[part 1 of 2: package /RootP_ASWC_A28]
AUTOSAR XML (schema 4-2-1)
package /RootP_ASWC_A28
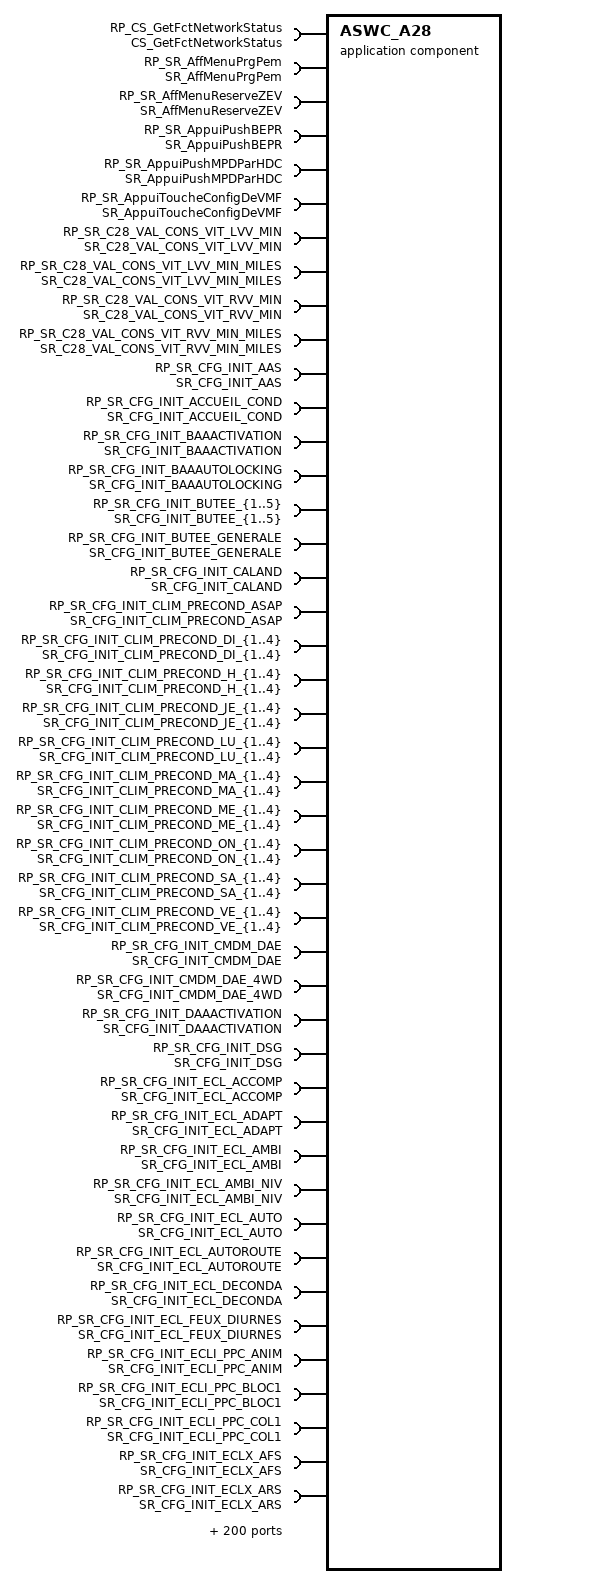
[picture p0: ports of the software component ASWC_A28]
  application sw component type ASWC_A28
    277 x provide/require port:
      PRP_SR_ButeeXvv{1..5}DeMenuPerso: nonqueued-receiver-com-spec{data-element=ButeeXvv{1..5}DeMenuPerso, enable-update=0, handle-data-status=1, handle-never-received=0, init-value=CONST_tBYTE_0:0}, provided-required-interface=SR_ButeeXvv{1..5}DeMenuPerso
      PRP_SR_DdeAccesJDADeVMF: nonqueued-receiver-com-spec{data-element=DdeAccesJDADeVMF, enable-update=0, handle-data-status=1, handle-never-received=0, init-value=CONST_tLOG_0:0}, provided-required-interface=SR_DdeAccesJDADeVMF
      PRP_SR_DdeAllumPlafDeVMF: nonqueued-receiver-com-spec{data-element=DdeAllumPlafDeVMF, enable-update=0, handle-data-status=1, handle-never-received=0, init-value=CONST_tLOG_0:0}, provided-required-interface=SR_DdeAllumPlafDeVMF
      PRP_SR_DdeBlackPanelDeVMF: nonqueued-receiver-com-spec{data-element=DdeBlackPanelDeVMF, enable-update=0, handle-data-status=1, handle-never-received=0, init-value=CONST_tLOG_0:0}, provided-required-interface=SR_DdeBlackPanelDeVMF
      PRP_SR_DdeCheckTcfg: nonqueued-receiver-com-spec{data-element=DdeCheckTcfg, enable-update=0, handle-data-status=1, handle-never-received=0, init-value=CONST_tLOG_0:0}, provided-required-interface=SR_DdeCheckTcfg
      PRP_SR_DdeColorisationCMBDeVMF: nonqueued-receiver-com-spec{data-element=DdeColorisationCMBDeVMF, enable-update=0, handle-data-status=1, handle-never-received=0, init-value=CONST_tLOG_0:0}, provided-required-interface=SR_DdeColorisationCMBDeVMF
      PRP_SR_DdeConfigToucheDeVMF: nonqueued-receiver-com-spec{data-element=DdeConfigToucheDeVMF, enable-update=0, handle-data-status=1, handle-never-received=0, init-value=CONST_tLOG_0:0}, provided-required-interface=SR_DdeConfigToucheDeVMF
      PRP_SR_DdePersoCMBDeVMF: nonqueued-receiver-com-spec{data-element=DdePersoCMBDeVMF, enable-update=0, handle-data-status=1, handle-never-received=0, init-value=CONST_tLOG_0:0}, provided-required-interface=SR_DdePersoCMBDeVMF
      PRP_SR_DispoDmdMenuPrecond: nonqueued-receiver-com-spec{data-element=DispoDmdMenuPrecond, enable-update=0, handle-data-status=1, handle-never-received=0, init-value=CONST_tLOG_0:0}, provided-required-interface=SR_DispoDmdMenuPrecond
      PRP_SR_DispoDmdMenuRecharge: nonqueued-receiver-com-spec{data-element=DispoDmdMenuRecharge, enable-update=0, handle-data-status=1, handle-never-received=0, init-value=CONST_tBYTE_0b01:0b01}, provided-required-interface=SR_DispoDmdMenuRecharge
      PRP_SR_DispoEtatMenuPrgPem: nonqueued-receiver-com-spec{data-element=DispoEtatMenuPrgPem, enable-update=0, handle-data-status=1, handle-never-received=0, init-value=CONST_tLOG_0:0}, provided-required-interface=SR_DispoEtatMenuPrgPem
      PRP_SR_DispoEtatMenuReserveZEV: nonqueued-receiver-com-spec{data-element=DispoEtatMenuReserveZEV, enable-update=0, handle-data-status=1, handle-never-received=0, init-value=CONST_tLOG_0:0}, provided-required-interface=SR_DispoEtatMenuReserveZEV
      PRP_SR_DmdmCGEPVReserveZEV: nonqueued-receiver-com-spec{data-element=DmdmCGEPVReserveZEV, enable-update=0, handle-data-status=1, handle-never-received=0, init-value=CONST_tLOG_0:0}, provided-required-interface=SR_DmdmCGEPVReserveZEV
      PRP_SR_DmdMenuSelPrgDi: nonqueued-receiver-com-spec{data-element=DmdMenuSelPrgDi, enable-update=0, handle-data-status=1, handle-never-received=0, init-value=CONST_tLOG_0:0}, provided-required-interface=SR_DmdMenuSelPrgDi
      PRP_SR_DmdMenuSelPrgJe: nonqueued-receiver-com-spec{data-element=DmdMenuSelPrgJe, enable-update=0, handle-data-status=1, handle-never-received=0, init-value=CONST_tLOG_0:0}, provided-required-interface=SR_DmdMenuSelPrgJe
      PRP_SR_DmdMenuSelPrgLu: nonqueued-receiver-com-spec{data-element=DmdMenuSelPrgLu, enable-update=0, handle-data-status=1, handle-never-received=0, init-value=CONST_tLOG_0:0}, provided-required-interface=SR_DmdMenuSelPrgLu
      PRP_SR_DmdMenuSelPrgMa: nonqueued-receiver-com-spec{data-element=DmdMenuSelPrgMa, enable-update=0, handle-data-status=1, handle-never-received=0, init-value=CONST_tLOG_0:0}, provided-required-interface=SR_DmdMenuSelPrgMa
      PRP_SR_DmdMenuSelPrgMe: nonqueued-receiver-com-spec{data-element=DmdMenuSelPrgMe, enable-update=0, handle-data-status=1, handle-never-received=0, init-value=CONST_tLOG_0:0}, provided-required-interface=SR_DmdMenuSelPrgMe
      PRP_SR_DmdMenuSelPrgSa: nonqueued-receiver-com-spec{data-element=DmdMenuSelPrgSa, enable-update=0, handle-data-status=1, handle-never-received=0, init-value=CONST_tLOG_0:0}, provided-required-interface=SR_DmdMenuSelPrgSa
      PRP_SR_DmdMenuSelPrgVe: nonqueued-receiver-com-spec{data-element=DmdMenuSelPrgVe, enable-update=0, handle-data-status=1, handle-never-received=0, init-value=CONST_tLOG_0:0}, provided-required-interface=SR_DmdMenuSelPrgVe
      PRP_SR_DmdmPrgHcEnd: nonqueued-receiver-com-spec{data-element=DmdmPrgHcEnd, enable-update=0, handle-data-status=1, handle-never-received=0, init-value=CONST_tDWORD_0:0}, provided-required-interface=SR_DmdmPrgHcEnd
      PRP_SR_DmdmPrgHcStart: nonqueued-receiver-com-spec{data-element=DmdmPrgHcStart, enable-update=0, handle-data-status=1, handle-never-received=0, init-value=CONST_tDWORD_0:0}, provided-required-interface=SR_DmdmPrgHcStart
      PRP_SR_DmdmPrgPemDi: nonqueued-receiver-com-spec{data-element=DmdmPrgPemDi, enable-update=0, handle-data-status=1, handle-never-received=0, init-value=CONST_tDWORD_0:0}, provided-required-interface=SR_DmdmPrgPemDi
      PRP_SR_DmdmPrgPemJe: nonqueued-receiver-com-spec{data-element=DmdmPrgPemJe, enable-update=0, handle-data-status=1, handle-never-received=0, init-value=CONST_tDWORD_0:0}, provided-required-interface=SR_DmdmPrgPemJe
      PRP_SR_DmdmPrgPemLu: nonqueued-receiver-com-spec{data-element=DmdmPrgPemLu, enable-update=0, handle-data-status=1, handle-never-received=0, init-value=CONST_tDWORD_0:0}, provided-required-interface=SR_DmdmPrgPemLu
      PRP_SR_DmdmPrgPemMa: nonqueued-receiver-com-spec{data-element=DmdmPrgPemMa, enable-update=0, handle-data-status=1, handle-never-received=0, init-value=CONST_tDWORD_0:0}, provided-required-interface=SR_DmdmPrgPemMa
      PRP_SR_DmdmPrgPemMe: nonqueued-receiver-com-spec{data-element=DmdmPrgPemMe, enable-update=0, handle-data-status=1, handle-never-received=0, init-value=CONST_tDWORD_0:0}, provided-required-interface=SR_DmdmPrgPemMe
      PRP_SR_DmdmPrgPemSa: nonqueued-receiver-com-spec{data-element=DmdmPrgPemSa, enable-update=0, handle-data-status=1, handle-never-received=0, init-value=CONST_tDWORD_0:0}, provided-required-interface=SR_DmdmPrgPemSa
      PRP_SR_DmdmPrgPemVe: nonqueued-receiver-com-spec{data-element=DmdmPrgPemVe, enable-update=0, handle-data-status=1, handle-never-received=0, init-value=CONST_tDWORD_0:0}, provided-required-interface=SR_DmdmPrgPemVe
      PRP_SR_EclAccompDeMenuPerso: nonqueued-receiver-com-spec{data-element=EclAccompDeMenuPerso, enable-update=0, handle-data-status=1, handle-never-received=0, init-value=CONST_t_cAccomp_0:0}, provided-required-interface=SR_EclAccompDeMenuPerso
      PRP_SR_EclDecondaDeMenuPerso: nonqueued-receiver-com-spec{data-element=EclDecondaDeMenuPerso, enable-update=0, handle-data-status=1, handle-never-received=0, init-value=CONST_t_cDeconda_0:0}, provided-required-interface=SR_EclDecondaDeMenuPerso
      PRP_SR_EtatMenuAccueilCond: nonqueued-receiver-com-spec{data-element=EtatMenuAccueilCond, enable-update=0, handle-data-status=1, handle-never-received=0, init-value=CONST_tLOG_0:0}, provided-required-interface=SR_EtatMenuAccueilCond
      PRP_SR_EtatMenuActButee{1..5}XVV: nonqueued-receiver-com-spec{data-element=EtatMenuActButee{1..5}XVV, enable-update=0, handle-data-status=1, handle-never-received=0, init-value=CONST_tLOG_0:0}, provided-required-interface=SR_EtatMenuActButee{1..5}XVV
      PRP_SR_EtatMenuActButeeGenXVV: nonqueued-receiver-com-spec{data-element=EtatMenuActButeeGenXVV, enable-update=0, handle-data-status=1, handle-never-received=0, init-value=CONST_tLOG_0:0}, provided-required-interface=SR_EtatMenuActButeeGenXVV
      PRP_SR_EtatMenuARCSensNiv: nonqueued-receiver-com-spec{data-element=EtatMenuARCSensNiv, enable-update=0, handle-data-status=1, handle-never-received=0, init-value=CONST_tBILOG_2:2}, provided-required-interface=SR_EtatMenuARCSensNiv
      PRP_SR_EtatMenuBAAActivation: nonqueued-receiver-com-spec{data-element=EtatMenuBAAActivation, enable-update=0, handle-data-status=1, handle-never-received=0, init-value=CONST_tLOG_0:0}, provided-required-interface=SR_EtatMenuBAAActivation
      PRP_SR_EtatMenuBAAAutolocking: nonqueued-receiver-com-spec{data-element=EtatMenuBAAAutolocking, enable-update=0, handle-data-status=1, handle-never-received=0, init-value=CONST_tLOG_0:0}, provided-required-interface=SR_EtatMenuBAAAutolocking
      PRP_SR_EtatMenuCLIM_PrecondASAP: nonqueued-receiver-com-spec{data-element=EtatMenuCLIM_PrecondASAP, enable-update=0, handle-data-status=1, handle-never-received=0, init-value=CONST_tLOG_0:0}, provided-required-interface=SR_EtatMenuCLIM_PrecondASAP
      PRP_SR_EtatMenuCLIM_PrecondDi{1..4}: nonqueued-receiver-com-spec{data-element=EtatMenuCLIM_PrecondDi{1..4}, enable-update=0, handle-data-status=1, handle-never-received=0, init-value=CONST_tLOG_0:0}, provided-required-interface=SR_EtatMenuCLIM_PrecondDi{1..4}
      PRP_SR_EtatMenuCLIM_PrecondH{1..4}: nonqueued-receiver-com-spec{data-element=EtatMenuCLIM_PrecondH{1..4}, enable-update=0, handle-data-status=1, handle-never-received=0, init-value=CONST_tWORD_0:0}, provided-required-interface=SR_EtatMenuCLIM_PrecondH{1..4}
      PRP_SR_EtatMenuCLIM_PrecondJe{1..4}: nonqueued-receiver-com-spec{data-element=EtatMenuCLIM_PrecondJe{1..4}, enable-update=0, handle-data-status=1, handle-never-received=0, init-value=CONST_tLOG_0:0}, provided-required-interface=SR_EtatMenuCLIM_PrecondJe{1..4}
      PRP_SR_EtatMenuCLIM_PrecondLu{1..4}: nonqueued-receiver-com-spec{data-element=EtatMenuCLIM_PrecondLu{1..4}, enable-update=0, handle-data-status=1, handle-never-received=0, init-value=CONST_tLOG_0:0}, provided-required-interface=SR_EtatMenuCLIM_PrecondLu{1..4}
      PRP_SR_EtatMenuCLIM_PrecondMa{1..4}: nonqueued-receiver-com-spec{data-element=EtatMenuCLIM_PrecondMa{1..4}, enable-update=0, handle-data-status=1, handle-never-received=0, init-value=CONST_tLOG_0:0}, provided-required-interface=SR_EtatMenuCLIM_PrecondMa{1..4}
      PRP_SR_EtatMenuCLIM_PrecondMe{1..4}: nonqueued-receiver-com-spec{data-element=EtatMenuCLIM_PrecondMe{1..4}, enable-update=0, handle-data-status=1, handle-never-received=0, init-value=CONST_tLOG_0:0}, provided-required-interface=SR_EtatMenuCLIM_PrecondMe{1..4}
      PRP_SR_EtatMenuCLIM_PrecondOn{1..4}: nonqueued-receiver-com-spec{data-element=EtatMenuCLIM_PrecondOn{1..4}, enable-update=0, handle-data-status=1, handle-never-received=0, init-value=CONST_tLOG_0:0}, provided-required-interface=SR_EtatMenuCLIM_PrecondOn{1..4}
      PRP_SR_EtatMenuCLIM_PrecondSa{1..4}: nonqueued-receiver-com-spec{data-element=EtatMenuCLIM_PrecondSa{1..4}, enable-update=0, handle-data-status=1, handle-never-received=0, init-value=CONST_tLOG_0:0}, provided-required-interface=SR_EtatMenuCLIM_PrecondSa{1..4}
      PRP_SR_EtatMenuCLIM_PrecondVe{1..4}: nonqueued-receiver-com-spec{data-element=EtatMenuCLIM_PrecondVe{1..4}, enable-update=0, handle-data-status=1, handle-never-received=0, init-value=CONST_tLOG_0:0}, provided-required-interface=SR_EtatMenuCLIM_PrecondVe{1..4}
      PRP_SR_EtatMenuDAAActivation: nonqueued-receiver-com-spec{data-element=EtatMenuDAAActivation, enable-update=0, handle-data-status=1, handle-never-received=0, init-value=CONST_tLOG_0:0}, provided-required-interface=SR_EtatMenuDAAActivation
      PRP_SR_EtatMenuDSG: nonqueued-receiver-com-spec{data-element=EtatMenuDSG, enable-update=0, handle-data-status=1, handle-never-received=0, init-value=CONST_tLOG_0:0}, provided-required-interface=SR_EtatMenuDSG
      PRP_SR_EtatMenuEclAccomp: nonqueued-receiver-com-spec{data-element=EtatMenuEclAccomp, enable-update=0, handle-data-status=1, handle-never-received=0, init-value=CONST_tLOG_0:0}, provided-required-interface=SR_EtatMenuEclAccomp
      PRP_SR_EtatMenuEclAccompTempo: nonqueued-receiver-com-spec{data-element=EtatMenuEclAccompTempo, enable-update=0, handle-data-status=1, handle-never-received=0, init-value=CONST_tBILOG_0:0}, provided-required-interface=SR_EtatMenuEclAccompTempo
      PRP_SR_EtatMenuEclAdapt: nonqueued-receiver-com-spec{data-element=EtatMenuEclAdapt, enable-update=0, handle-data-status=1, handle-never-received=0, init-value=CONST_tLOG_0:0}, provided-required-interface=SR_EtatMenuEclAdapt
      PRP_SR_EtatMenuEclAmbi: nonqueued-receiver-com-spec{data-element=EtatMenuEclAmbi, enable-update=0, handle-data-status=1, handle-never-received=0, init-value=CONST_tLOG_0:0}, provided-required-interface=SR_EtatMenuEclAmbi
      PRP_SR_EtatMenuEclAmbiNiv: nonqueued-receiver-com-spec{data-element=EtatMenuEclAmbiNiv, enable-update=0, handle-data-status=1, handle-never-received=0, init-value=CONST_tBYTE_6:6}, provided-required-interface=SR_EtatMenuEclAmbiNiv
      PRP_SR_EtatMenuEclAuto: nonqueued-receiver-com-spec{data-element=EtatMenuEclAuto, enable-update=0, handle-data-status=1, handle-never-received=0, init-value=CONST_tLOG_0:0}, provided-required-interface=SR_EtatMenuEclAuto
      PRP_SR_EtatMenuEclAutoroute: nonqueued-receiver-com-spec{data-element=EtatMenuEclAutoroute, enable-update=0, handle-data-status=1, handle-never-received=0, init-value=CONST_tLOG_0:0}, provided-required-interface=SR_EtatMenuEclAutoroute
      PRP_SR_EtatMenuEclCaland: nonqueued-receiver-com-spec{data-element=EtatMenuEclCaland, enable-update=0, handle-data-status=1, handle-never-received=0, init-value=CONST_tLOG_0:0}, provided-required-interface=SR_EtatMenuEclCaland
      PRP_SR_EtatMenuEclDeconda: nonqueued-receiver-com-spec{data-element=EtatMenuEclDeconda, enable-update=0, handle-data-status=1, handle-never-received=0, init-value=CONST_tLOG_0:0}, provided-required-interface=SR_EtatMenuEclDeconda
      PRP_SR_EtatMenuEclDecondaTempo: nonqueued-receiver-com-spec{data-element=EtatMenuEclDecondaTempo, enable-update=0, handle-data-status=1, handle-never-received=0, init-value=CONST_tBILOG_0:0}, provided-required-interface=SR_EtatMenuEclDecondaTempo
      PRP_SR_EtatMenuECLI_PPC_ANIM: nonqueued-receiver-com-spec{data-element=EtatMenuECLI_PPC_ANIM, enable-update=0, handle-data-status=1, handle-never-received=0, init-value=CONST_tBYTE_0:0}, provided-required-interface=SR_EtatMenuECLI_PPC_ANIM
      PRP_SR_EtatMenuECLI_PPC_BLOC1: nonqueued-receiver-com-spec{data-element=EtatMenuECLI_PPC_BLOC1, enable-update=0, handle-data-status=1, handle-never-received=0, init-value=CONST_tLOG_0:0}, provided-required-interface=SR_EtatMenuECLI_PPC_BLOC1
      PRP_SR_EtatMenuECLI_PPC_COL1: nonqueued-receiver-com-spec{data-element=EtatMenuECLI_PPC_COL1, enable-update=0, handle-data-status=1, handle-never-received=0, init-value=CONST_tBYTE_0:0}, provided-required-interface=SR_EtatMenuECLI_PPC_COL1
      PRP_SR_EtatMenuECLX_AFS: nonqueued-receiver-com-spec{data-element=EtatMenuECLX_AFS, enable-update=0, handle-data-status=1, handle-never-received=0, init-value=CONST_tLOG_0:0}, provided-required-interface=SR_EtatMenuECLX_AFS
      PRP_SR_EtatMenuECLX_ARS: nonqueued-receiver-com-spec{data-element=EtatMenuECLX_ARS, enable-update=0, handle-data-status=1, handle-never-received=0, init-value=CONST_tLOG_0:0}, provided-required-interface=SR_EtatMenuECLX_ARS
      PRP_SR_EtatMenuECLX_ECL_CAFR: nonqueued-receiver-com-spec{data-element=EtatMenuECLX_ECL_CAFR, enable-update=0, handle-data-status=1, handle-never-received=0, init-value=CONST_tLOG_0:0}, provided-required-interface=SR_EtatMenuECLX_ECL_CAFR
      PRP_SR_EtatMenuEssuiVitMar: nonqueued-receiver-com-spec{data-element=EtatMenuEssuiVitMar, enable-update=0, handle-data-status=1, handle-never-received=0, init-value=CONST_tLOG_0:0}, provided-required-interface=SR_EtatMenuEssuiVitMar
      PRP_SR_EtatMenuFARC: nonqueued-receiver-com-spec{data-element=EtatMenuFARC, enable-update=0, handle-data-status=1, handle-never-received=0, init-value=CONST_tLOG_0:0}, provided-required-interface=SR_EtatMenuFARC
      PRP_SR_EtatMenuFeuxDiurne: nonqueued-receiver-com-spec{data-element=EtatMenuFeuxDiurne, enable-update=0, handle-data-status=1, handle-never-received=0, init-value=CONST_tLOG_0:0}, provided-required-interface=SR_EtatMenuFeuxDiurne
      PRP_SR_EtatMenuFSEAuto: nonqueued-receiver-com-spec{data-element=EtatMenuFSEAuto, enable-update=0, handle-data-status=1, handle-never-received=0, init-value=CONST_tLOG_0:0}, provided-required-interface=SR_EtatMenuFSEAuto
      PRP_SR_EtatMenuGAV_AMLA: nonqueued-receiver-com-spec{data-element=EtatMenuGAV_AMLA, enable-update=0, handle-data-status=1, handle-never-received=0, init-value=CONST_tLOG_0:0}, provided-required-interface=SR_EtatMenuGAV_AMLA
      PRP_SR_EtatMenuILV: nonqueued-receiver-com-spec{data-element=EtatMenuILV, enable-update=0, handle-data-status=1, handle-never-received=0, init-value=CONST_tLOG_0:0}, provided-required-interface=SR_EtatMenuILV
      PRP_SR_EtatMenuILV_ETSR: nonqueued-receiver-com-spec{data-element=EtatMenuILV_ETSR, enable-update=0, handle-data-status=1, handle-never-received=0, init-value=CONST_tLOG_0:0}, provided-required-interface=SR_EtatMenuILV_ETSR
      PRP_SR_EtatMenuIMA: nonqueued-receiver-com-spec{data-element=EtatMenuIMA, enable-update=0, handle-data-status=1, handle-never-received=0, init-value=CONST_tLOG_0:0}, provided-required-interface=SR_EtatMenuIMA
      PRP_SR_EtatMenuInfoParamDispo: nonqueued-receiver-com-spec{data-element=EtatMenuInfoParamDispo, enable-update=0, handle-data-status=1, handle-never-received=0, init-value=CONST_tLOG_0:0}, provided-required-interface=SR_EtatMenuInfoParamDispo
      PRP_SR_EtatMenuInfoUniteLangueDispo: nonqueued-receiver-com-spec{data-element=EtatMenuInfoUniteLangueDispo, enable-update=0, handle-data-status=1, handle-never-received=0, init-value=CONST_tLOG_0:0}, provided-required-interface=SR_EtatMenuInfoUniteLangueDispo
      PRP_SR_EtatMenuInfoVitLvvDispo: nonqueued-receiver-com-spec{data-element=EtatMenuInfoVitLvvDispo, enable-update=0, handle-data-status=1, handle-never-received=0, init-value=CONST_tLOG_0:0}, provided-required-interface=SR_EtatMenuInfoVitLvvDispo
      PRP_SR_EtatMenuInfoVitRvvDispo: nonqueued-receiver-com-spec{data-element=EtatMenuInfoVitRvvDispo, enable-update=0, handle-data-status=1, handle-never-received=0, init-value=CONST_tLOG_0:0}, provided-required-interface=SR_EtatMenuInfoVitRvvDispo
      PRP_SR_EtatMenuInfoXVVDispo: nonqueued-receiver-com-spec{data-element=EtatMenuInfoXVVDispo, enable-update=0, handle-data-status=1, handle-never-received=0, init-value=CONST_tLOG_0:0}, provided-required-interface=SR_EtatMenuInfoXVVDispo
      PRP_SR_EtatMenuINV_ADSD: nonqueued-receiver-com-spec{data-element=EtatMenuINV_ADSD, enable-update=0, handle-data-status=1, handle-never-received=0, init-value=CONST_tLOG_0:0}, provided-required-interface=SR_EtatMenuINV_ADSD
      PRP_SR_EtatMenuLangueVehicule: nonqueued-receiver-com-spec{data-element=EtatMenuLangueVehicule, enable-update=0, handle-data-status=1, handle-never-received=0, init-value=CONST_tBYTE_0:0}, provided-required-interface=SR_EtatMenuLangueVehicule
      PRP_SR_EtatMenuMotoVolAr: nonqueued-receiver-com-spec{data-element=EtatMenuMotoVolAr, enable-update=0, handle-data-status=1, handle-never-received=0, init-value=CONST_tLOG_0:0}, provided-required-interface=SR_EtatMenuMotoVolAr
      PRP_SR_EtatMenuPresenceARC: nonqueued-receiver-com-spec{data-element=EtatMenuPresenceARC, enable-update=0, handle-data-status=1, handle-never-received=0, init-value=CONST_tLOG_0:0}, provided-required-interface=SR_EtatMenuPresenceARC
      PRP_SR_EtatMenuPRV_MODE: nonqueued-receiver-com-spec{data-element=EtatMenuPRV_MODE, enable-update=0, handle-data-status=1, handle-never-received=0, init-value=CONST_tBYTE_0:0}, provided-required-interface=SR_EtatMenuPRV_MODE
      PRP_SR_EtatMenuReserveZEV: nonqueued-receiver-com-spec{data-element=EtatMenuReserveZEV, enable-update=0, handle-data-status=1, handle-never-received=0, init-value=CONST_tLOG_0:0}, provided-required-interface=SR_EtatMenuReserveZEV
      PRP_SR_EtatMenuRTAB_EnergyRec: nonqueued-receiver-com-spec{data-element=EtatMenuRTAB_EnergyRec, enable-update=0, handle-data-status=1, handle-never-received=0, init-value=CONST_tBYTE_0b01:0b01}, provided-required-interface=SR_EtatMenuRTAB_EnergyRec
      PRP_SR_EtatMenuRTAB_RechargeHDeb: nonqueued-receiver-com-spec{data-element=EtatMenuRTAB_RechargeHDeb, enable-update=0, handle-data-status=1, handle-never-received=0, init-value=CONST_tWORD_0:0}, provided-required-interface=SR_EtatMenuRTAB_RechargeHDeb
      PRP_SR_EtatMenuRTAB_TypeRec: nonqueued-receiver-com-spec{data-element=EtatMenuRTAB_TypeRec, enable-update=0, handle-data-status=1, handle-never-received=0, init-value=CONST_tLOG_0:0}, provided-required-interface=SR_EtatMenuRTAB_TypeRec
      PRP_SR_EtatMenuSelecArriere: nonqueued-receiver-com-spec{data-element=EtatMenuSelecArriere, enable-update=0, handle-data-status=1, handle-never-received=0, init-value=CONST_tLOG_0:0}, provided-required-interface=SR_EtatMenuSelecArriere
      PRP_SR_EtatMenuSelecCabine: nonqueued-receiver-com-spec{data-element=EtatMenuSelecCabine, enable-update=0, handle-data-status=1, handle-never-received=0, init-value=CONST_tLOG_0:0}, provided-required-interface=SR_EtatMenuSelecCabine
      PRP_SR_EtatMenuSelecOuvPlip: nonqueued-receiver-com-spec{data-element=EtatMenuSelecOuvPlip, enable-update=0, handle-data-status=1, handle-never-received=0, init-value=CONST_tLOG_0:0}, provided-required-interface=SR_EtatMenuSelecOuvPlip
      PRP_SR_EtatMenuSelReserveZEV: nonqueued-receiver-com-spec{data-element=EtatMenuSelReserveZEV, enable-update=0, handle-data-status=1, handle-never-received=0, init-value=CONST_tLOG_0:0}, provided-required-interface=SR_EtatMenuSelReserveZEV
      PRP_SR_EtatMenuSonPoly: nonqueued-receiver-com-spec{data-element=EtatMenuSonPoly, enable-update=0, handle-data-status=1, handle-never-received=0, init-value=CONST_tBILOG_0:0}, provided-required-interface=SR_EtatMenuSonPoly
      PRP_SR_EtatMenuStatusAAS: nonqueued-receiver-com-spec{data-element=EtatMenuStatusAAS, enable-update=0, handle-data-status=1, handle-never-received=0, init-value=CONST_tLOG_0:0}, provided-required-interface=SR_EtatMenuStatusAAS
      PRP_SR_EtatMenuStatusSAM: nonqueued-receiver-com-spec{data-element=EtatMenuStatusSAM, enable-update=0, handle-data-status=1, handle-never-received=0, init-value=CONST_tLOG_0:0}, provided-required-interface=SR_EtatMenuStatusSAM
      PRP_SR_EtatMenuTCFG: nonqueued-receiver-com-spec{data-element=EtatMenuTCFG, enable-update=0, handle-data-status=1, handle-never-received=0, init-value=CONST_tBYTE_0:0}, provided-required-interface=SR_EtatMenuTCFG
      PRP_SR_EtatMenuUniteConso: nonqueued-receiver-com-spec{data-element=EtatMenuUniteConso, enable-update=0, handle-data-status=1, handle-never-received=0, init-value=CONST_tLOG_0:0}, provided-required-interface=SR_EtatMenuUniteConso
      PRP_SR_EtatMenuUniteDistance: nonqueued-receiver-com-spec{data-element=EtatMenuUniteDistance, enable-update=0, handle-data-status=1, handle-never-received=0, init-value=CONST_tLOG_0:0}, provided-required-interface=SR_EtatMenuUniteDistance
      PRP_SR_EtatMenuUniteTemperature: nonqueued-receiver-com-spec{data-element=EtatMenuUniteTemperature, enable-update=0, handle-data-status=1, handle-never-received=0, init-value=CONST_tLOG_0:0}, provided-required-interface=SR_EtatMenuUniteTemperature
      PRP_SR_EtatMenuUniteVolume: nonqueued-receiver-com-spec{data-element=EtatMenuUniteVolume, enable-update=0, handle-data-status=1, handle-never-received=0, init-value=CONST_tLOG_0:0}, provided-required-interface=SR_EtatMenuUniteVolume
      PRP_SR_EtatMenuVitesse{1..5}XVV: nonqueued-receiver-com-spec{data-element=EtatMenuVitesse{1..5}XVV, enable-update=0, handle-data-status=1, handle-never-received=0, init-value=CONST_tBYTE_0:0}, provided-required-interface=SR_EtatMenuVitesse{1..5}XVV
      PRP_SR_EtatMenuVitLvv{1..6}: nonqueued-receiver-com-spec{data-element=EtatMenuVitLvv{1..6}, enable-update=0, handle-data-status=1, handle-never-received=0, init-value=CONST_tBYTE_0xFF:255}, provided-required-interface=SR_EtatMenuVitLvv{1..6}
      PRP_SR_EtatMenuVitRvv{1..6}: nonqueued-receiver-com-spec{data-element=EtatMenuVitRvv{1..6}, enable-update=0, handle-data-status=1, handle-never-received=0, init-value=CONST_tBYTE_0xFF:255}, provided-required-interface=SR_EtatMenuVitRvv{1..6}
      PRP_SR_EtatMenuVTOR_IRV: nonqueued-receiver-com-spec{data-element=EtatMenuVTOR_IRV, enable-update=0, handle-data-status=1, handle-never-received=0, init-value=CONST_tLOG_0:0}, provided-required-interface=SR_EtatMenuVTOR_IRV
      PRP_SR_S360_Envoi: nonqueued-receiver-com-spec{data-element=S360_Envoi, enable-update=0, handle-data-status=1, handle-never-received=0, init-value=CONST_tBILOG_0:0}, provided-required-interface=SR_S360_Envoi
      PRP_SR_S360_OCTET_{1..8}: nonqueued-receiver-com-spec{data-element=S360_OCTET_{1..8}, enable-update=0, handle-data-status=1, handle-never-received=0, init-value=CONST_tBYTE_0:0}, provided-required-interface=SR_S360_OCTET_{1..8}
      PRP_SR_S3A0_Recu: nonqueued-receiver-com-spec{data-element=S3A0_Recu, enable-update=0, handle-data-status=1, handle-never-received=0, init-value=CONST_tBILOG_0:0}, provided-required-interface=SR_S3A0_Recu
      PRP_SR_SEC_AccueilDeMenuPerso: nonqueued-receiver-com-spec{data-element=SEC_AccueilDeMenuPerso, enable-update=0, handle-data-status=1, handle-never-received=0, init-value=CONST_tLOG_0:0}, provided-required-interface=SR_SEC_AccueilDeMenuPerso
      PRP_SR_SEC_ActButee{1..5}XVV: nonqueued-receiver-com-spec{data-element=SEC_ActButee{1..5}XVV, enable-update=0, handle-data-status=1, handle-never-received=0, init-value=CONST_tLOG_0:0}, provided-required-interface=SR_SEC_ActButee{1..5}XVV
      PRP_SR_SEC_ActButeeGenXVV: nonqueued-receiver-com-spec{data-element=SEC_ActButeeGenXVV, enable-update=0, handle-data-status=1, handle-never-received=0, init-value=CONST_tLOG_0:0}, provided-required-interface=SR_SEC_ActButeeGenXVV
      PRP_SR_SEC_ActivationARCDeMenuPerso: nonqueued-receiver-com-spec{data-element=SEC_ActivationARCDeMenuPerso, enable-update=0, handle-data-status=1, handle-never-received=0, init-value=CONST_tLOG_1:1}, provided-required-interface=SR_SEC_ActivationARCDeMenuPerso
      PRP_SR_SEC_BAAActivationDeMenuPerso: nonqueued-receiver-com-spec{data-element=SEC_BAAActivationDeMenuPerso, enable-update=0, handle-data-status=1, handle-never-received=0, init-value=CONST_tLOG_0:0}, provided-required-interface=SR_SEC_BAAActivationDeMenuPerso
      PRP_SR_SEC_BAAAutolockingDeMenuPerso: nonqueued-receiver-com-spec{data-element=SEC_BAAAutolockingDeMenuPerso, enable-update=0, handle-data-status=1, handle-never-received=0, init-value=CONST_tLOG_0:0}, provided-required-interface=SR_SEC_BAAAutolockingDeMenuPerso
      PRP_SR_SEC_CLIM_PrecASAPDeMenuPerso: nonqueued-receiver-com-spec{data-element=SEC_CLIM_PrecASAPDeMenuPerso, enable-update=0, handle-data-status=1, handle-never-received=0, init-value=CONST_tLOG_0:0}, provided-required-interface=SR_SEC_CLIM_PrecASAPDeMenuPerso
      PRP_SR_SEC_CLIM_PrecH{1..4}DeMenuPerso: nonqueued-receiver-com-spec{data-element=SEC_CLIM_PrecH{1..4}DeMenuPerso, enable-update=0, handle-data-status=1, handle-never-received=0, init-value=CONST_tWORD_0:0}, provided-required-interface=SR_SEC_CLIM_PrecH{1..4}DeMenuPerso
      PRP_SR_SEC_CLIM_PrecOn{1..4}DeMenuPerso: nonqueued-receiver-com-spec{data-element=SEC_CLIM_PrecOn{1..4}DeMenuPerso, enable-update=0, handle-data-status=1, handle-never-received=0, init-value=CONST_tLOG_0:0}, provided-required-interface=SR_SEC_CLIM_PrecOn{1..4}DeMenuPerso
      PRP_SR_SEC_CLIMPrecPrg{1..4}DeMenuPerso: nonqueued-receiver-com-spec{data-element=SEC_CLIMPrecPrg{1..4}DeMenuPerso, enable-update=0, handle-data-status=1, handle-never-received=0, init-value=CONST_tWORD_0:0}, provided-required-interface=SR_SEC_CLIMPrecPrg{1..4}DeMenuPerso
      PRP_SR_SEC_CLIMPrecSem{1..4}DeMenuPerso: nonqueued-receiver-com-spec{data-element=SEC_CLIMPrecSem{1..4}DeMenuPerso, enable-update=0, handle-data-status=1, handle-never-received=0, init-value=CONST_tBYTE_0:0}, provided-required-interface=SR_SEC_CLIMPrecSem{1..4}DeMenuPerso
      PRP_SR_SEC_CMDM_DAE_4WDDeMenuPerso: nonqueued-receiver-com-spec{data-element=SEC_CMDM_DAE_4WDDeMenuPerso, enable-update=0, handle-data-status=1, handle-never-received=0, init-value=CONST_t_cDAE_0:0}, provided-required-interface=SR_SEC_CMDM_DAE_4WDDeMenuPerso
      PRP_SR_SEC_CMDM_DAEDeMenuPerso: nonqueued-receiver-com-spec{data-element=SEC_CMDM_DAEDeMenuPerso, enable-update=0, handle-data-status=1, handle-never-received=0, init-value=CONST_t_cDAE_0:0}, provided-required-interface=SR_SEC_CMDM_DAEDeMenuPerso
      PRP_SR_SEC_DAAActivationDeMenuPerso: nonqueued-receiver-com-spec{data-element=SEC_DAAActivationDeMenuPerso, enable-update=0, handle-data-status=1, handle-never-received=0, init-value=CONST_tLOG_0:0}, provided-required-interface=SR_SEC_DAAActivationDeMenuPerso
      PRP_SR_SEC_DecondaSelectDeMenuPerso: nonqueued-receiver-com-spec{data-element=SEC_DecondaSelectDeMenuPerso, enable-update=0, handle-data-status=1, handle-never-received=0, init-value=CONST_tLOG_0:0}, provided-required-interface=SR_SEC_DecondaSelectDeMenuPerso
      PRP_SR_SEC_DSGDeMenuPerso: nonqueued-receiver-com-spec{data-element=SEC_DSGDeMenuPerso, enable-update=0, handle-data-status=1, handle-never-received=0, init-value=CONST_tLOG_0:0}, provided-required-interface=SR_SEC_DSGDeMenuPerso
      PRP_SR_SEC_EclAccomp: nonqueued-receiver-com-spec{data-element=SEC_EclAccomp, enable-update=0, handle-data-status=1, handle-never-received=0, init-value=CONST_tLOG_0:0}, provided-required-interface=SR_SEC_EclAccomp
      PRP_SR_SEC_EclAccompTempo: nonqueued-receiver-com-spec{data-element=SEC_EclAccompTempo, enable-update=0, handle-data-status=1, handle-never-received=0, init-value=CONST_tBYTE_0:0}, provided-required-interface=SR_SEC_EclAccompTempo
      PRP_SR_SEC_EclAdaptDeMenuPerso: nonqueued-receiver-com-spec{data-element=SEC_EclAdaptDeMenuPerso, enable-update=0, handle-data-status=1, handle-never-received=0, init-value=CONST_tLOG_0:0}, provided-required-interface=SR_SEC_EclAdaptDeMenuPerso
      PRP_SR_SEC_EclAFSDeMenuPerso: nonqueued-receiver-com-spec{data-element=SEC_EclAFSDeMenuPerso, enable-update=0, handle-data-status=1, handle-never-received=0, init-value=CONST_tLOG_0:0}, provided-required-interface=SR_SEC_EclAFSDeMenuPerso
      PRP_SR_SEC_EclAmbiDeMenuPerso: nonqueued-receiver-com-spec{data-element=SEC_EclAmbiDeMenuPerso, enable-update=0, handle-data-status=1, handle-never-received=0, init-value=CONST_tLOG_0:0}, provided-required-interface=SR_SEC_EclAmbiDeMenuPerso
      PRP_SR_SEC_EclAmbiNivDeMenuPerso: nonqueued-receiver-com-spec{data-element=SEC_EclAmbiNivDeMenuPerso, enable-update=0, handle-data-status=1, handle-never-received=0, init-value=CONST_tBYTE_3:3}, provided-required-interface=SR_SEC_EclAmbiNivDeMenuPerso
      PRP_SR_SEC_EclARSDeMenuPerso: nonqueued-receiver-com-spec{data-element=SEC_EclARSDeMenuPerso, enable-update=0, handle-data-status=1, handle-never-received=0, init-value=CONST_tLOG_0:0}, provided-required-interface=SR_SEC_EclARSDeMenuPerso
      PRP_SR_SEC_EclAutoDeMenuPerso: nonqueued-receiver-com-spec{data-element=SEC_EclAutoDeMenuPerso, enable-update=0, handle-data-status=1, handle-never-received=0, init-value=CONST_tLOG_0:0}, provided-required-interface=SR_SEC_EclAutoDeMenuPerso
      PRP_SR_SEC_EclAutorouteDeMenuPerso: nonqueued-receiver-com-spec{data-element=SEC_EclAutorouteDeMenuPerso, enable-update=0, handle-data-status=1, handle-never-received=0, init-value=CONST_tLOG_0:0}, provided-required-interface=SR_SEC_EclAutorouteDeMenuPerso
      PRP_SR_SEC_EclCalandDeMenuPerso: nonqueued-receiver-com-spec{data-element=SEC_EclCalandDeMenuPerso, enable-update=0, handle-data-status=1, handle-never-received=0, init-value=CONST_tBILOG_0:0}, provided-required-interface=SR_SEC_EclCalandDeMenuPerso
      PRP_SR_SEC_EclDeconda: nonqueued-receiver-com-spec{data-element=SEC_EclDeconda, enable-update=0, handle-data-status=1, handle-never-received=0, init-value=CONST_tLOG_0:0}, provided-required-interface=SR_SEC_EclDeconda
      PRP_SR_SEC_EclDecondaTempo: nonqueued-receiver-com-spec{data-element=SEC_EclDecondaTempo, enable-update=0, handle-data-status=1, handle-never-received=0, init-value=CONST_tBYTE_0:0}, provided-required-interface=SR_SEC_EclDecondaTempo
      PRP_SR_SEC_ECLI_PPC_ANIMDeMenuPerso: nonqueued-receiver-com-spec{data-element=SEC_ECLI_PPC_ANIMDeMenuPerso, enable-update=0, handle-data-status=1, handle-never-received=0, init-value=CONST_tBYTE_0:0}, provided-required-interface=SR_SEC_ECLI_PPC_ANIMDeMenuPerso
      PRP_SR_SEC_ECLI_PPC_BLOC1DeMenuPerso: nonqueued-receiver-com-spec{data-element=SEC_ECLI_PPC_BLOC1DeMenuPerso, enable-update=0, handle-data-status=1, handle-never-received=0, init-value=CONST_tLOG_0:0}, provided-required-interface=SR_SEC_ECLI_PPC_BLOC1DeMenuPerso
      PRP_SR_SEC_ECLI_PPC_COL1DeMenuPerso: nonqueued-receiver-com-spec{data-element=SEC_ECLI_PPC_COL1DeMenuPerso, enable-update=0, handle-data-status=1, handle-never-received=0, init-value=CONST_tBYTE_1:1}, provided-required-interface=SR_SEC_ECLI_PPC_COL1DeMenuPerso
      PRP_SR_SEC_ECLX_ECL_CAFRDeMenuPerso: nonqueued-receiver-com-spec{data-element=SEC_ECLX_ECL_CAFRDeMenuPerso, enable-update=0, handle-data-status=1, handle-never-received=0, init-value=CONST_tLOG_0:0}, provided-required-interface=SR_SEC_ECLX_ECL_CAFRDeMenuPerso
      PRP_SR_SEC_EssuiVitMarDeMenuPerso: nonqueued-receiver-com-spec{data-element=SEC_EssuiVitMarDeMenuPerso, enable-update=0, handle-data-status=1, handle-never-received=0, init-value=CONST_tLOG_0:0}, provided-required-interface=SR_SEC_EssuiVitMarDeMenuPerso
      PRP_SR_SEC_FARCDeMenuPerso: nonqueued-receiver-com-spec{data-element=SEC_FARCDeMenuPerso, enable-update=0, handle-data-status=1, handle-never-received=0, init-value=CONST_tLOG_0:0}, provided-required-interface=SR_SEC_FARCDeMenuPerso
      PRP_SR_SEC_FctToucheCfgDeMenuPerso: nonqueued-receiver-com-spec{data-element=SEC_FctToucheCfgDeMenuPerso, enable-update=0, handle-data-status=1, handle-never-received=0, init-value=CONST_t_cFTCG_0:0}, provided-required-interface=SR_SEC_FctToucheCfgDeMenuPerso
      PRP_SR_SEC_FeuxDiurneDeMenuPerso: nonqueued-receiver-com-spec{data-element=SEC_FeuxDiurneDeMenuPerso, enable-update=0, handle-data-status=1, handle-never-received=0, init-value=CONST_tLOG_0:0}, provided-required-interface=SR_SEC_FeuxDiurneDeMenuPerso
      PRP_SR_SEC_FSEAutoDeMenuPerso: nonqueued-receiver-com-spec{data-element=SEC_FSEAutoDeMenuPerso, enable-update=0, handle-data-status=1, handle-never-received=0, init-value=CONST_tLOG_0:0}, provided-required-interface=SR_SEC_FSEAutoDeMenuPerso
      PRP_SR_SEC_GAV_AMLADeMenuPerso: nonqueued-receiver-com-spec{data-element=SEC_GAV_AMLADeMenuPerso, enable-update=0, handle-data-status=1, handle-never-received=0, init-value=CONST_tLOG_0:0}, provided-required-interface=SR_SEC_GAV_AMLADeMenuPerso
      PRP_SR_SEC_ILVDeMenuPerso: nonqueued-receiver-com-spec{data-element=SEC_ILVDeMenuPerso, enable-update=0, handle-data-status=1, handle-never-received=0, init-value=CONST_tLOG_0:0}, provided-required-interface=SR_SEC_ILVDeMenuPerso
      PRP_SR_SEC_ILV_ETSRDeMenuPerso: nonqueued-receiver-com-spec{data-element=SEC_ILV_ETSRDeMenuPerso, enable-update=0, handle-data-status=1, handle-never-received=0, init-value=CONST_tLOG_0:0}, provided-required-interface=SR_SEC_ILV_ETSRDeMenuPerso
      PRP_SR_SEC_IMADeMenuPerso: nonqueued-receiver-com-spec{data-element=SEC_IMADeMenuPerso, enable-update=0, handle-data-status=1, handle-never-received=0, init-value=CONST_tLOG_0:0}, provided-required-interface=SR_SEC_IMADeMenuPerso
      PRP_SR_SEC_InhibitionAASDeMenuPerso: nonqueued-receiver-com-spec{data-element=SEC_InhibitionAASDeMenuPerso, enable-update=0, handle-data-status=1, handle-never-received=0, init-value=CONST_tLOG_0:0}, provided-required-interface=SR_SEC_InhibitionAASDeMenuPerso
      PRP_SR_SEC_InhibitionSAMDeMenuPerso: nonqueued-receiver-com-spec{data-element=SEC_InhibitionSAMDeMenuPerso, enable-update=0, handle-data-status=1, handle-never-received=0, init-value=CONST_tLOG_0:0}, provided-required-interface=SR_SEC_InhibitionSAMDeMenuPerso
      PRP_SR_SEC_INV_ADSDDeMenuPerso: nonqueued-receiver-com-spec{data-element=SEC_INV_ADSDDeMenuPerso, enable-update=0, handle-data-status=1, handle-never-received=0, init-value=CONST_tLOG_0:0}, provided-required-interface=SR_SEC_INV_ADSDDeMenuPerso
      PRP_SR_SEC_LangueVehicule: nonqueued-receiver-com-spec{data-element=SEC_LangueVehicule, enable-update=0, handle-data-status=1, handle-never-received=0, init-value=CONST_tBYTE_0:0}, provided-required-interface=SR_SEC_LangueVehicule
      PRP_SR_SEC_MotoVolArDeMenuPerso: nonqueued-receiver-com-spec{data-element=SEC_MotoVolArDeMenuPerso, enable-update=0, handle-data-status=1, handle-never-received=0, init-value=CONST_tLOG_0:0}, provided-required-interface=SR_SEC_MotoVolArDeMenuPerso
      PRP_SR_SEC_PrgPemDiDeMenuPerso: nonqueued-receiver-com-spec{data-element=SEC_PrgPemDiDeMenuPerso, enable-update=0, handle-data-status=1, handle-never-received=0, init-value=CONST_tDWORD_0:0}, provided-required-interface=SR_SEC_PrgPemDiDeMenuPerso
      PRP_SR_SEC_PrgPemJeDeMenuPerso: nonqueued-receiver-com-spec{data-element=SEC_PrgPemJeDeMenuPerso, enable-update=0, handle-data-status=1, handle-never-received=0, init-value=CONST_tDWORD_0:0}, provided-required-interface=SR_SEC_PrgPemJeDeMenuPerso
      PRP_SR_SEC_PrgPemLuDeMenuPerso: nonqueued-receiver-com-spec{data-element=SEC_PrgPemLuDeMenuPerso, enable-update=0, handle-data-status=1, handle-never-received=0, init-value=CONST_tDWORD_0:0}, provided-required-interface=SR_SEC_PrgPemLuDeMenuPerso
      PRP_SR_SEC_PrgPemMaDeMenuPerso: nonqueued-receiver-com-spec{data-element=SEC_PrgPemMaDeMenuPerso, enable-update=0, handle-data-status=1, handle-never-received=0, init-value=CONST_tDWORD_0:0}, provided-required-interface=SR_SEC_PrgPemMaDeMenuPerso
      PRP_SR_SEC_PrgPemMeDeMenuPerso: nonqueued-receiver-com-spec{data-element=SEC_PrgPemMeDeMenuPerso, enable-update=0, handle-data-status=1, handle-never-received=0, init-value=CONST_tDWORD_0:0}, provided-required-interface=SR_SEC_PrgPemMeDeMenuPerso
      PRP_SR_SEC_PrgPemSaDeMenuPerso: nonqueued-receiver-com-spec{data-element=SEC_PrgPemSaDeMenuPerso, enable-update=0, handle-data-status=1, handle-never-received=0, init-value=CONST_tDWORD_0:0}, provided-required-interface=SR_SEC_PrgPemSaDeMenuPerso
      PRP_SR_SEC_PrgPemVeDeMenuPerso: nonqueued-receiver-com-spec{data-element=SEC_PrgPemVeDeMenuPerso, enable-update=0, handle-data-status=1, handle-never-received=0, init-value=CONST_tDWORD_0:0}, provided-required-interface=SR_SEC_PrgPemVeDeMenuPerso
      PRP_SR_SEC_PRV_MODEDeMenuPerso: nonqueued-receiver-com-spec{data-element=SEC_PRV_MODEDeMenuPerso, enable-update=0, handle-data-status=1, handle-never-received=0, init-value=CONST_tBYTE_0:0}, provided-required-interface=SR_SEC_PRV_MODEDeMenuPerso
      PRP_SR_SEC_ReserveZEVDeMenuPerso: nonqueued-receiver-com-spec{data-element=SEC_ReserveZEVDeMenuPerso, enable-update=0, handle-data-status=1, handle-never-received=0, init-value=CONST_tBYTE_0:0}, provided-required-interface=SR_SEC_ReserveZEVDeMenuPerso
      PRP_SR_SEC_RTABDeMenuPerso: nonqueued-receiver-com-spec{data-element=SEC_RTABDeMenuPerso, enable-update=0, handle-data-status=1, handle-never-received=0, init-value=CONST_tLOG_0:0}, provided-required-interface=SR_SEC_RTABDeMenuPerso
      PRP_SR_SEC_RTAB_EnergyRecDeMenuPerso: nonqueued-receiver-com-spec{data-element=SEC_RTAB_EnergyRecDeMenuPerso, enable-update=0, handle-data-status=1, handle-never-received=0, init-value=CONST_tBYTE_1:1}, provided-required-interface=SR_SEC_RTAB_EnergyRecDeMenuPerso
      PRP_SR_SEC_RTAB_RecHDebDeMenuPerso: nonqueued-receiver-com-spec{data-element=SEC_RTAB_RecHDebDeMenuPerso, enable-update=0, handle-data-status=1, handle-never-received=0, init-value=CONST_tWORD_0:0}, provided-required-interface=SR_SEC_RTAB_RecHDebDeMenuPerso
      PRP_SR_SEC_RTAB_TypeRecDeMenuPerso: nonqueued-receiver-com-spec{data-element=SEC_RTAB_TypeRecDeMenuPerso, enable-update=0, handle-data-status=1, handle-never-received=0, init-value=CONST_tLOG_0:0}, provided-required-interface=SR_SEC_RTAB_TypeRecDeMenuPerso
      PRP_SR_SEC_SelectOuvARDeMenuPerso: nonqueued-receiver-com-spec{data-element=SEC_SelectOuvARDeMenuPerso, enable-update=0, handle-data-status=1, handle-never-received=0, init-value=CONST_tLOG_0:0}, provided-required-interface=SR_SEC_SelectOuvARDeMenuPerso
      PRP_SR_SEC_SelReserveZEVDeMenuPerso: nonqueued-receiver-com-spec{data-element=SEC_SelReserveZEVDeMenuPerso, enable-update=0, handle-data-status=1, handle-never-received=0, init-value=CONST_tLOG_0:0}, provided-required-interface=SR_SEC_SelReserveZEVDeMenuPerso
      PRP_SR_SEC_SensibiliteARCDeMenuPerso: nonqueued-receiver-com-spec{data-element=SEC_SensibiliteARCDeMenuPerso, enable-update=0, handle-data-status=1, handle-never-received=0, init-value=CONST_tQUARTET_3:3}, provided-required-interface=SR_SEC_SensibiliteARCDeMenuPerso
      PRP_SR_SEC_SonPolyphDeMenuPerso: nonqueued-receiver-com-spec{data-element=SEC_SonPolyphDeMenuPerso, enable-update=0, handle-data-status=1, handle-never-received=0, init-value=CONST_tBILOG_0:0}, provided-required-interface=SR_SEC_SonPolyphDeMenuPerso
      PRP_SR_SEC_UniteConso: nonqueued-receiver-com-spec{data-element=SEC_UniteConso, enable-update=0, handle-data-status=1, handle-never-received=0, init-value=CONST_tLOG_0:0}, provided-required-interface=SR_SEC_UniteConso
      PRP_SR_SEC_UniteDistance: nonqueued-receiver-com-spec{data-element=SEC_UniteDistance, enable-update=0, handle-data-status=1, handle-never-received=0, init-value=CONST_tLOG_0:0}, provided-required-interface=SR_SEC_UniteDistance
      PRP_SR_SEC_UniteTemperature: nonqueued-receiver-com-spec{data-element=SEC_UniteTemperature, enable-update=0, handle-data-status=1, handle-never-received=0, init-value=CONST_tLOG_0:0}, provided-required-interface=SR_SEC_UniteTemperature
      PRP_SR_SEC_UniteVolume: nonqueued-receiver-com-spec{data-element=SEC_UniteVolume, enable-update=0, handle-data-status=1, handle-never-received=0, init-value=CONST_tLOG_0:0}, provided-required-interface=SR_SEC_UniteVolume
      PRP_SR_SEC_VAM_ECS_MODEDeMenuPerso: nonqueued-receiver-com-spec{data-element=SEC_VAM_ECS_MODEDeMenuPerso, enable-update=0, handle-data-status=1, handle-never-received=0, init-value=CONST_tLOG_0:0}, provided-required-interface=SR_SEC_VAM_ECS_MODEDeMenuPerso
      PRP_SR_SEC_Vitesse{1..5}XVV: nonqueued-receiver-com-spec{data-element=SEC_Vitesse{1..5}XVV, enable-update=0, handle-data-status=1, handle-never-received=0, init-value=CONST_tBYTE_0:0}, provided-required-interface=SR_SEC_Vitesse{1..5}XVV
      PRP_SR_SEC_VitLvv1DeMenuPerso: nonqueued-receiver-com-spec{data-element=SEC_VitLvv1DeMenuPerso, enable-update=0, handle-data-status=1, handle-never-received=0, init-value=CONST_tBYTE_0:0}, provided-required-interface=SR_SEC_VitLvv1DeMenuPerso
      PRP_SR_SEC_VitLvv1MilesDeMenuPerso: nonqueued-receiver-com-spec{data-element=SEC_VitLvv1MilesDeMenuPerso, enable-update=0, handle-data-status=1, handle-never-received=0, init-value=CONST_tBYTE_0:0}, provided-required-interface=SR_SEC_VitLvv1MilesDeMenuPerso
      PRP_SR_SEC_VitLvv2DeMenuPerso: nonqueued-receiver-com-spec{data-element=SEC_VitLvv2DeMenuPerso, enable-update=0, handle-data-status=1, handle-never-received=0, init-value=CONST_tBYTE_0:0}, provided-required-interface=SR_SEC_VitLvv2DeMenuPerso
      PRP_SR_SEC_VitLvv2MilesDeMenuPerso: nonqueued-receiver-com-spec{data-element=SEC_VitLvv2MilesDeMenuPerso, enable-update=0, handle-data-status=1, handle-never-received=0, init-value=CONST_tBYTE_0:0}, provided-required-interface=SR_SEC_VitLvv2MilesDeMenuPerso
      PRP_SR_SEC_VitLvv3DeMenuPerso: nonqueued-receiver-com-spec{data-element=SEC_VitLvv3DeMenuPerso, enable-update=0, handle-data-status=1, handle-never-received=0, init-value=CONST_tBYTE_0:0}, provided-required-interface=SR_SEC_VitLvv3DeMenuPerso
      PRP_SR_SEC_VitLvv3MilesDeMenuPerso: nonqueued-receiver-com-spec{data-element=SEC_VitLvv3MilesDeMenuPerso, enable-update=0, handle-data-status=1, handle-never-received=0, init-value=CONST_tBYTE_0:0}, provided-required-interface=SR_SEC_VitLvv3MilesDeMenuPerso
      PRP_SR_SEC_VitLvv4DeMenuPerso: nonqueued-receiver-com-spec{data-element=SEC_VitLvv4DeMenuPerso, enable-update=0, handle-data-status=1, handle-never-received=0, init-value=CONST_tBYTE_0:0}, provided-required-interface=SR_SEC_VitLvv4DeMenuPerso
      PRP_SR_SEC_VitLvv4MilesDeMenuPerso: nonqueued-receiver-com-spec{data-element=SEC_VitLvv4MilesDeMenuPerso, enable-update=0, handle-data-status=1, handle-never-received=0, init-value=CONST_tBYTE_0:0}, provided-required-interface=SR_SEC_VitLvv4MilesDeMenuPerso
      PRP_SR_SEC_VitLvv5DeMenuPerso: nonqueued-receiver-com-spec{data-element=SEC_VitLvv5DeMenuPerso, enable-update=0, handle-data-status=1, handle-never-received=0, init-value=CONST_tBYTE_0:0}, provided-required-interface=SR_SEC_VitLvv5DeMenuPerso
      PRP_SR_SEC_VitLvv5MilesDeMenuPerso: nonqueued-receiver-com-spec{data-element=SEC_VitLvv5MilesDeMenuPerso, enable-update=0, handle-data-status=1, handle-never-received=0, init-value=CONST_tBYTE_0:0}, provided-required-interface=SR_SEC_VitLvv5MilesDeMenuPerso
      PRP_SR_SEC_VitLvv6DeMenuPerso: nonqueued-receiver-com-spec{data-element=SEC_VitLvv6DeMenuPerso, enable-update=0, handle-data-status=1, handle-never-received=0, init-value=CONST_tBYTE_0:0}, provided-required-interface=SR_SEC_VitLvv6DeMenuPerso
      PRP_SR_SEC_VitLvv6MilesDeMenuPerso: nonqueued-receiver-com-spec{data-element=SEC_VitLvv6MilesDeMenuPerso, enable-update=0, handle-data-status=1, handle-never-received=0, init-value=CONST_tBYTE_0:0}, provided-required-interface=SR_SEC_VitLvv6MilesDeMenuPerso
      PRP_SR_SEC_VitRvv1DeMenuPerso: nonqueued-receiver-com-spec{data-element=SEC_VitRvv1DeMenuPerso, enable-update=0, handle-data-status=1, handle-never-received=0, init-value=CONST_tBYTE_0:0}, provided-required-interface=SR_SEC_VitRvv1DeMenuPerso
      PRP_SR_SEC_VitRvv1MilesDeMenuPerso: nonqueued-receiver-com-spec{data-element=SEC_VitRvv1MilesDeMenuPerso, enable-update=0, handle-data-status=1, handle-never-received=0, init-value=CONST_tBYTE_0:0}, provided-required-interface=SR_SEC_VitRvv1MilesDeMenuPerso
      PRP_SR_SEC_VitRvv2DeMenuPerso: nonqueued-receiver-com-spec{data-element=SEC_VitRvv2DeMenuPerso, enable-update=0, handle-data-status=1, handle-never-received=0, init-value=CONST_tBYTE_0:0}, provided-required-interface=SR_SEC_VitRvv2DeMenuPerso
      PRP_SR_SEC_VitRvv2MilesDeMenuPerso: nonqueued-receiver-com-spec{data-element=SEC_VitRvv2MilesDeMenuPerso, enable-update=0, handle-data-status=1, handle-never-received=0, init-value=CONST_tBYTE_0:0}, provided-required-interface=SR_SEC_VitRvv2MilesDeMenuPerso
      PRP_SR_SEC_VitRvv3DeMenuPerso: nonqueued-receiver-com-spec{data-element=SEC_VitRvv3DeMenuPerso, enable-update=0, handle-data-status=1, handle-never-received=0, init-value=CONST_tBYTE_0:0}, provided-required-interface=SR_SEC_VitRvv3DeMenuPerso
      PRP_SR_SEC_VitRvv3MilesDeMenuPerso: nonqueued-receiver-com-spec{data-element=SEC_VitRvv3MilesDeMenuPerso, enable-update=0, handle-data-status=1, handle-never-received=0, init-value=CONST_tBYTE_0:0}, provided-required-interface=SR_SEC_VitRvv3MilesDeMenuPerso
      PRP_SR_SEC_VitRvv4DeMenuPerso: nonqueued-receiver-com-spec{data-element=SEC_VitRvv4DeMenuPerso, enable-update=0, handle-data-status=1, handle-never-received=0, init-value=CONST_tBYTE_0:0}, provided-required-interface=SR_SEC_VitRvv4DeMenuPerso
      PRP_SR_SEC_VitRvv4MilesDeMenuPerso: nonqueued-receiver-com-spec{data-element=SEC_VitRvv4MilesDeMenuPerso, enable-update=0, handle-data-status=1, handle-never-received=0, init-value=CONST_tBYTE_0:0}, provided-required-interface=SR_SEC_VitRvv4MilesDeMenuPerso
      PRP_SR_SEC_VitRvv5DeMenuPerso: nonqueued-receiver-com-spec{data-element=SEC_VitRvv5DeMenuPerso, enable-update=0, handle-data-status=1, handle-never-received=0, init-value=CONST_tBYTE_0:0}, provided-required-interface=SR_SEC_VitRvv5DeMenuPerso
      PRP_SR_SEC_VitRvv5MilesDeMenuPerso: nonqueued-receiver-com-spec{data-element=SEC_VitRvv5MilesDeMenuPerso, enable-update=0, handle-data-status=1, handle-never-received=0, init-value=CONST_tBYTE_0:0}, provided-required-interface=SR_SEC_VitRvv5MilesDeMenuPerso
      PRP_SR_SEC_VitRvv6DeMenuPerso: nonqueued-receiver-com-spec{data-element=SEC_VitRvv6DeMenuPerso, enable-update=0, handle-data-status=1, handle-never-received=0, init-value=CONST_tBYTE_0:0}, provided-required-interface=SR_SEC_VitRvv6DeMenuPerso
      PRP_SR_SEC_VitRvv6MilesDeMenuPerso: nonqueued-receiver-com-spec{data-element=SEC_VitRvv6MilesDeMenuPerso, enable-update=0, handle-data-status=1, handle-never-received=0, init-value=CONST_tBYTE_0:0}, provided-required-interface=SR_SEC_VitRvv6MilesDeMenuPerso
      PRP_SR_SEC_VTOR_IRVDeMenuPerso: nonqueued-receiver-com-spec{data-element=SEC_VTOR_IRVDeMenuPerso, enable-update=0, handle-data-status=1, handle-never-received=0, init-value=CONST_tLOG_0:0}, provided-required-interface=SR_SEC_VTOR_IRVDeMenuPerso
      PRP_SR_SEC_ZCSelectDeMenuPerso: nonqueued-receiver-com-spec{data-element=SEC_ZCSelectDeMenuPerso, enable-update=0, handle-data-status=1, handle-never-received=0, init-value=CONST_tLOG_0:0}, provided-required-interface=SR_SEC_ZCSelectDeMenuPerso
    320 x require port:
      RP_CS_GetFctNetworkStatus: required-interface=CS_GetFctNetworkStatus
      RP_SR_AffMenuPrgPem: nonqueued-receiver-com-spec{data-element=AffMenuPrgPem, enable-update=0, handle-data-status=1, handle-never-received=0, init-value=CONST_tLOG_0:0}, required-interface=SR_AffMenuPrgPem
      RP_SR_AffMenuReserveZEV: nonqueued-receiver-com-spec{data-element=AffMenuReserveZEV, enable-update=0, handle-data-status=1, handle-never-received=0, init-value=CONST_tLOG_0:0}, required-interface=SR_AffMenuReserveZEV
      RP_SR_AppuiPushBEPR: nonqueued-receiver-com-spec{data-element=AppuiPushBEPR, enable-update=0, handle-data-status=1, handle-never-received=0, init-value=CONST_tLOG_0:0}, required-interface=SR_AppuiPushBEPR
      RP_SR_AppuiPushMPDParHDC: nonqueued-receiver-com-spec{data-element=AppuiPushMPDParHDC, enable-update=0, handle-data-status=1, handle-never-received=0, init-value=CONST_tLOG_0:0}, required-interface=SR_AppuiPushMPDParHDC
      RP_SR_AppuiToucheConfigDeVMF: nonqueued-receiver-com-spec{data-element=AppuiToucheConfigDeVMF, enable-update=0, handle-data-status=1, handle-never-received=0, init-value=CONST_tLOG_0:0}, required-interface=SR_AppuiToucheConfigDeVMF
      RP_SR_C28_VAL_CONS_VIT_LVV_MIN: nonqueued-receiver-com-spec{data-element=C28_VAL_CONS_VIT_LVV_MIN, enable-update=0, handle-data-status=1, handle-never-received=0, init-value=CONST_t_C28_VAL_CONS_VIT_LVV_MIN_30:30}, required-interface=SR_C28_VAL_CONS_VIT_LVV_MIN
      RP_SR_C28_VAL_CONS_VIT_LVV_MIN_MILES: nonqueued-receiver-com-spec{data-element=C28_VAL_CONS_VIT_LVV_MIN_MILES, enable-update=0, handle-data-status=1, handle-never-received=0, init-value=CONST_t_C28_VAL_CONS_VIT_LVV_MIN_MILES_50:50}, required-interface=SR_C28_VAL_CONS_VIT_LVV_MIN_MILES
      RP_SR_C28_VAL_CONS_VIT_RVV_MIN: nonqueued-receiver-com-spec{data-element=C28_VAL_CONS_VIT_RVV_MIN, enable-update=0, handle-data-status=1, handle-never-received=0, init-value=CONST_t_C28_VAL_CONS_VIT_RVV_MIN_40:40}, required-interface=SR_C28_VAL_CONS_VIT_RVV_MIN
      RP_SR_C28_VAL_CONS_VIT_RVV_MIN_MILES: nonqueued-receiver-com-spec{data-element=C28_VAL_CONS_VIT_RVV_MIN_MILES, enable-update=0, handle-data-status=1, handle-never-received=0, init-value=CONST_t_C28_VAL_CONS_VIT_RVV_MIN_MILES_50:50}, required-interface=SR_C28_VAL_CONS_VIT_RVV_MIN_MILES
      RP_SR_CFG_INIT_AAS: nonqueued-receiver-com-spec{data-element=CFG_INIT_AAS, enable-update=0, handle-data-status=1, handle-never-received=0, init-value=CONST_tLOG_1:1}, required-interface=SR_CFG_INIT_AAS
      RP_SR_CFG_INIT_ACCUEIL_COND: nonqueued-receiver-com-spec{data-element=CFG_INIT_ACCUEIL_COND, enable-update=0, handle-data-status=1, handle-never-received=0, init-value=CONST_tLOG_1:1}, required-interface=SR_CFG_INIT_ACCUEIL_COND
      RP_SR_CFG_INIT_BAAACTIVATION: nonqueued-receiver-com-spec{data-element=CFG_INIT_BAAACTIVATION, enable-update=0, handle-data-status=1, handle-never-received=0, init-value=CONST_tLOG_1:1}, required-interface=SR_CFG_INIT_BAAACTIVATION
      RP_SR_CFG_INIT_BAAAUTOLOCKING: nonqueued-receiver-com-spec{data-element=CFG_INIT_BAAAUTOLOCKING, enable-update=0, handle-data-status=1, handle-never-received=0, init-value=CONST_tLOG_1:1}, required-interface=SR_CFG_INIT_BAAAUTOLOCKING
      RP_SR_CFG_INIT_BUTEE_{1..5}: nonqueued-receiver-com-spec{data-element=CFG_INIT_BUTEE_{1..5}, enable-update=0, handle-data-status=1, handle-never-received=0, init-value=CONST_tLOG_1:1}, required-interface=SR_CFG_INIT_BUTEE_{1..5}
      RP_SR_CFG_INIT_BUTEE_GENERALE: nonqueued-receiver-com-spec{data-element=CFG_INIT_BUTEE_GENERALE, enable-update=0, handle-data-status=1, handle-never-received=0, init-value=CONST_tLOG_0:0}, required-interface=SR_CFG_INIT_BUTEE_GENERALE
      RP_SR_CFG_INIT_CALAND: nonqueued-receiver-com-spec{data-element=CFG_INIT_CALAND, enable-update=0, handle-data-status=1, handle-never-received=0, init-value=CONST_tLOG_1:1}, required-interface=SR_CFG_INIT_CALAND
      RP_SR_CFG_INIT_CLIM_PRECOND_ASAP: nonqueued-receiver-com-spec{data-element=CFG_INIT_CLIM_PRECOND_ASAP, enable-update=0, handle-data-status=1, handle-never-received=0, init-value=CONST_tLOG_0:0}, required-interface=SR_CFG_INIT_CLIM_PRECOND_ASAP
      RP_SR_CFG_INIT_CLIM_PRECOND_DI_{1..4}: nonqueued-receiver-com-spec{data-element=CFG_INIT_CLIM_PRECOND_DI_{1..4}, enable-update=0, handle-data-status=1, handle-never-received=0, init-value=CONST_tLOG_0:0}, required-interface=SR_CFG_INIT_CLIM_PRECOND_DI_{1..4}
      RP_SR_CFG_INIT_CLIM_PRECOND_H_{1..4}: nonqueued-receiver-com-spec{data-element=CFG_INIT_CLIM_PRECOND_H_{1..4}, enable-update=0, handle-data-status=1, handle-never-received=0, init-value=CONST_tWORD_0:0}, required-interface=SR_CFG_INIT_CLIM_PRECOND_H_{1..4}
      RP_SR_CFG_INIT_CLIM_PRECOND_JE_{1..4}: nonqueued-receiver-com-spec{data-element=CFG_INIT_CLIM_PRECOND_JE_{1..4}, enable-update=0, handle-data-status=1, handle-never-received=0, init-value=CONST_tLOG_0:0}, required-interface=SR_CFG_INIT_CLIM_PRECOND_JE_{1..4}
      RP_SR_CFG_INIT_CLIM_PRECOND_LU_{1..4}: nonqueued-receiver-com-spec{data-element=CFG_INIT_CLIM_PRECOND_LU_{1..4}, enable-update=0, handle-data-status=1, handle-never-received=0, init-value=CONST_tLOG_0:0}, required-interface=SR_CFG_INIT_CLIM_PRECOND_LU_{1..4}
      RP_SR_CFG_INIT_CLIM_PRECOND_MA_{1..4}: nonqueued-receiver-com-spec{data-element=CFG_INIT_CLIM_PRECOND_MA_{1..4}, enable-update=0, handle-data-status=1, handle-never-received=0, init-value=CONST_tLOG_0:0}, required-interface=SR_CFG_INIT_CLIM_PRECOND_MA_{1..4}
      RP_SR_CFG_INIT_CLIM_PRECOND_ME_{1..4}: nonqueued-receiver-com-spec{data-element=CFG_INIT_CLIM_PRECOND_ME_{1..4}, enable-update=0, handle-data-status=1, handle-never-received=0, init-value=CONST_tLOG_0:0}, required-interface=SR_CFG_INIT_CLIM_PRECOND_ME_{1..4}
      RP_SR_CFG_INIT_CLIM_PRECOND_ON_{1..4}: nonqueued-receiver-com-spec{data-element=CFG_INIT_CLIM_PRECOND_ON_{1..4}, enable-update=0, handle-data-status=1, handle-never-received=0, init-value=CONST_tLOG_0:0}, required-interface=SR_CFG_INIT_CLIM_PRECOND_ON_{1..4}
      RP_SR_CFG_INIT_CLIM_PRECOND_SA_{1..4}: nonqueued-receiver-com-spec{data-element=CFG_INIT_CLIM_PRECOND_SA_{1..4}, enable-update=0, handle-data-status=1, handle-never-received=0, init-value=CONST_tLOG_0:0}, required-interface=SR_CFG_INIT_CLIM_PRECOND_SA_{1..4}
      RP_SR_CFG_INIT_CLIM_PRECOND_VE_{1..4}: nonqueued-receiver-com-spec{data-element=CFG_INIT_CLIM_PRECOND_VE_{1..4}, enable-update=0, handle-data-status=1, handle-never-received=0, init-value=CONST_tLOG_0:0}, required-interface=SR_CFG_INIT_CLIM_PRECOND_VE_{1..4}
      RP_SR_CFG_INIT_CMDM_DAE: nonqueued-receiver-com-spec{data-element=CFG_INIT_CMDM_DAE, enable-update=0, handle-data-status=1, handle-never-received=0, init-value=CONST_tLOG_1:1}, required-interface=SR_CFG_INIT_CMDM_DAE
      RP_SR_CFG_INIT_CMDM_DAE_4WD: nonqueued-receiver-com-spec{data-element=CFG_INIT_CMDM_DAE_4WD, enable-update=0, handle-data-status=1, handle-never-received=0, init-value=CONST_tLOG_1:1}, required-interface=SR_CFG_INIT_CMDM_DAE_4WD
      RP_SR_CFG_INIT_DAAACTIVATION: nonqueued-receiver-com-spec{data-element=CFG_INIT_DAAACTIVATION, enable-update=0, handle-data-status=1, handle-never-received=0, init-value=CONST_tLOG_1:1}, required-interface=SR_CFG_INIT_DAAACTIVATION
      RP_SR_CFG_INIT_DSG: nonqueued-receiver-com-spec{data-element=CFG_INIT_DSG, enable-update=0, handle-data-status=1, handle-never-received=0, init-value=CONST_tLOG_0:0}, required-interface=SR_CFG_INIT_DSG
      RP_SR_CFG_INIT_ECL_ACCOMP: nonqueued-receiver-com-spec{data-element=CFG_INIT_ECL_ACCOMP, enable-update=0, handle-data-status=1, handle-never-received=0, init-value=CONST_tLOG_0:0}, required-interface=SR_CFG_INIT_ECL_ACCOMP
      RP_SR_CFG_INIT_ECL_ADAPT: nonqueued-receiver-com-spec{data-element=CFG_INIT_ECL_ADAPT, enable-update=0, handle-data-status=1, handle-never-received=0, init-value=CONST_tLOG_1:1}, required-interface=SR_CFG_INIT_ECL_ADAPT
      RP_SR_CFG_INIT_ECL_AMBI: nonqueued-receiver-com-spec{data-element=CFG_INIT_ECL_AMBI, enable-update=0, handle-data-status=1, handle-never-received=0, init-value=CONST_tLOG_1:1}, required-interface=SR_CFG_INIT_ECL_AMBI
      RP_SR_CFG_INIT_ECL_AMBI_NIV: nonqueued-receiver-com-spec{data-element=CFG_INIT_ECL_AMBI_NIV, enable-update=0, handle-data-status=1, handle-never-received=0, init-value=6}, required-interface=SR_CFG_INIT_ECL_AMBI_NIV
      RP_SR_CFG_INIT_ECL_AUTO: nonqueued-receiver-com-spec{data-element=CFG_INIT_ECL_AUTO, enable-update=0, handle-data-status=1, handle-never-received=0, init-value=CONST_tLOG_0:0}, required-interface=SR_CFG_INIT_ECL_AUTO
      RP_SR_CFG_INIT_ECL_AUTOROUTE: nonqueued-receiver-com-spec{data-element=CFG_INIT_ECL_AUTOROUTE, enable-update=0, handle-data-status=1, handle-never-received=0, init-value=CONST_tLOG_1:1}, required-interface=SR_CFG_INIT_ECL_AUTOROUTE
      RP_SR_CFG_INIT_ECL_DECONDA: nonqueued-receiver-com-spec{data-element=CFG_INIT_ECL_DECONDA, enable-update=0, handle-data-status=1, handle-never-received=0, init-value=CONST_tLOG_0:0}, required-interface=SR_CFG_INIT_ECL_DECONDA
      RP_SR_CFG_INIT_ECL_FEUX_DIURNES: nonqueued-receiver-com-spec{data-element=CFG_INIT_ECL_FEUX_DIURNES, enable-update=0, handle-data-status=1, handle-never-received=0, init-value=CONST_tLOG_0:0}, required-interface=SR_CFG_INIT_ECL_FEUX_DIURNES
      RP_SR_CFG_INIT_ECLI_PPC_ANIM: nonqueued-receiver-com-spec{data-element=CFG_INIT_ECLI_PPC_ANIM, enable-update=0, handle-data-status=1, handle-never-received=0, init-value=CONST_tBYTE_1:1}, required-interface=SR_CFG_INIT_ECLI_PPC_ANIM
      RP_SR_CFG_INIT_ECLI_PPC_BLOC1: nonqueued-receiver-com-spec{data-element=CFG_INIT_ECLI_PPC_BLOC1, enable-update=0, handle-data-status=1, handle-never-received=0, init-value=CONST_tLOG_1:1}, required-interface=SR_CFG_INIT_ECLI_PPC_BLOC1
      RP_SR_CFG_INIT_ECLI_PPC_COL1: nonqueued-receiver-com-spec{data-element=CFG_INIT_ECLI_PPC_COL1, enable-update=0, handle-data-status=1, handle-never-received=0, init-value=CONST_tBYTE_1:1}, required-interface=SR_CFG_INIT_ECLI_PPC_COL1
      RP_SR_CFG_INIT_ECLX_AFS: nonqueued-receiver-com-spec{data-element=CFG_INIT_ECLX_AFS, enable-update=0, handle-data-status=1, handle-never-received=0, init-value=CONST_tLOG_0:0}, required-interface=SR_CFG_INIT_ECLX_AFS
      RP_SR_CFG_INIT_ECLX_ARS: nonqueued-receiver-com-spec{data-element=CFG_INIT_ECLX_ARS, enable-update=0, handle-data-status=1, handle-never-received=0, init-value=CONST_tLOG_0:0}, required-interface=SR_CFG_INIT_ECLX_ARS
      RP_SR_CFG_INIT_ECLX_ECL_CAFR: nonqueued-receiver-com-spec{data-element=CFG_INIT_ECLX_ECL_CAFR, enable-update=0, handle-data-status=1, handle-never-received=0, init-value=CONST_tLOG_1:1}, required-interface=SR_CFG_INIT_ECLX_ECL_CAFR
      RP_SR_CFG_INIT_ESSUIE_VIT_MAR: nonqueued-receiver-com-spec{data-element=CFG_INIT_ESSUIE_VIT_MAR, enable-update=0, handle-data-status=1, handle-never-received=0, init-value=CONST_tLOG_0:0}, required-interface=SR_CFG_INIT_ESSUIE_VIT_MAR
      RP_SR_CFG_INIT_FARC: nonqueued-receiver-com-spec{data-element=CFG_INIT_FARC, enable-update=0, handle-data-status=1, handle-never-received=0, init-value=CONST_tLOG_0:0}, required-interface=SR_CFG_INIT_FARC
      RP_SR_CFG_INIT_FSE_AUTO: nonqueued-receiver-com-spec{data-element=CFG_INIT_FSE_AUTO, enable-update=0, handle-data-status=1, handle-never-received=0, init-value=CONST_tLOG_1:1}, required-interface=SR_CFG_INIT_FSE_AUTO
      RP_SR_CFG_INIT_GAV_AMLA: nonqueued-receiver-com-spec{data-element=CFG_INIT_GAV_AMLA, enable-update=0, handle-data-status=1, handle-never-received=0, init-value=CONST_tLOG_0:0}, required-interface=SR_CFG_INIT_GAV_AMLA
      RP_SR_CFG_INIT_HARMONIE_SON: nonqueued-receiver-com-spec{data-element=CFG_INIT_HARMONIE_SON, enable-update=0, handle-data-status=1, handle-never-received=0, init-value=0}, required-interface=SR_CFG_INIT_HARMONIE_SON
      RP_SR_CFG_INIT_ILV: nonqueued-receiver-com-spec{data-element=CFG_INIT_ILV, enable-update=0, handle-data-status=1, handle-never-received=0, init-value=CONST_tLOG_1:1}, required-interface=SR_CFG_INIT_ILV
      RP_SR_CFG_INIT_ILV_ETSR: nonqueued-receiver-com-spec{data-element=CFG_INIT_ILV_ETSR, enable-update=0, handle-data-status=1, handle-never-received=0, init-value=CONST_tLOG_1:1}, required-interface=SR_CFG_INIT_ILV_ETSR
      RP_SR_CFG_INIT_IMA: nonqueued-receiver-com-spec{data-element=CFG_INIT_IMA, enable-update=0, handle-data-status=1, handle-never-received=0, init-value=CONST_tLOG_1:1}, required-interface=SR_CFG_INIT_IMA
      RP_SR_CFG_INIT_INV_ADSD: nonqueued-receiver-com-spec{data-element=CFG_INIT_INV_ADSD, enable-update=0, handle-data-status=1, handle-never-received=0, init-value=CONST_tLOG_1:1}, required-interface=SR_CFG_INIT_INV_ADSD
      RP_SR_CFG_INIT_LANGUE_VHL: nonqueued-receiver-com-spec{data-element=CFG_INIT_LANGUE_VHL, enable-update=0, handle-data-status=1, handle-never-received=0, init-value=0}, required-interface=SR_CFG_INIT_LANGUE_VHL
      RP_SR_CFG_INIT_MENU_HC_END: nonqueued-receiver-com-spec{data-element=CFG_INIT_MENU_HC_END, enable-update=0, handle-data-status=1, handle-never-received=0, init-value=420}, required-interface=SR_CFG_INIT_MENU_HC_END
      RP_SR_CFG_INIT_MENU_HC_START: nonqueued-receiver-com-spec{data-element=CFG_INIT_MENU_HC_START, enable-update=0, handle-data-status=1, handle-never-received=0, init-value=1380}, required-interface=SR_CFG_INIT_MENU_HC_START
      RP_SR_CFG_INIT_MENU_PRG_PEM_DI: nonqueued-receiver-com-spec{data-element=CFG_INIT_MENU_PRG_PEM_DI, enable-update=0, handle-data-status=1, handle-never-received=0, init-value=480}, required-interface=SR_CFG_INIT_MENU_PRG_PEM_DI
      RP_SR_CFG_INIT_MENU_PRG_PEM_JE: nonqueued-receiver-com-spec{data-element=CFG_INIT_MENU_PRG_PEM_JE, enable-update=0, handle-data-status=1, handle-never-received=0, init-value=480}, required-interface=SR_CFG_INIT_MENU_PRG_PEM_JE
      RP_SR_CFG_INIT_MENU_PRG_PEM_LU: nonqueued-receiver-com-spec{data-element=CFG_INIT_MENU_PRG_PEM_LU, enable-update=0, handle-data-status=1, handle-never-received=0, init-value=480}, required-interface=SR_CFG_INIT_MENU_PRG_PEM_LU
      RP_SR_CFG_INIT_MENU_PRG_PEM_MA: nonqueued-receiver-com-spec{data-element=CFG_INIT_MENU_PRG_PEM_MA, enable-update=0, handle-data-status=1, handle-never-received=0, init-value=480}, required-interface=SR_CFG_INIT_MENU_PRG_PEM_MA
      RP_SR_CFG_INIT_MENU_PRG_PEM_ME: nonqueued-receiver-com-spec{data-element=CFG_INIT_MENU_PRG_PEM_ME, enable-update=0, handle-data-status=1, handle-never-received=0, init-value=480}, required-interface=SR_CFG_INIT_MENU_PRG_PEM_ME
      RP_SR_CFG_INIT_MENU_PRG_PEM_SA: nonqueued-receiver-com-spec{data-element=CFG_INIT_MENU_PRG_PEM_SA, enable-update=0, handle-data-status=1, handle-never-received=0, init-value=480}, required-interface=SR_CFG_INIT_MENU_PRG_PEM_SA
      RP_SR_CFG_INIT_MENU_PRG_PEM_VE: nonqueued-receiver-com-spec{data-element=CFG_INIT_MENU_PRG_PEM_VE, enable-update=0, handle-data-status=1, handle-never-received=0, init-value=480}, required-interface=SR_CFG_INIT_MENU_PRG_PEM_VE
      RP_SR_CFG_INIT_MENU_SEL_HC: nonqueued-receiver-com-spec{data-element=CFG_INIT_MENU_SEL_HC, enable-update=0, handle-data-status=1, handle-never-received=0, init-value=CONST_tLOG_1:1}, required-interface=SR_CFG_INIT_MENU_SEL_HC
      RP_SR_CFG_INIT_MENU_SEL_PRG_PEM_DI: nonqueued-receiver-com-spec{data-element=CFG_INIT_MENU_SEL_PRG_PEM_DI, enable-update=0, handle-data-status=1, handle-never-received=0, init-value=CONST_tLOG_1:1}, required-interface=SR_CFG_INIT_MENU_SEL_PRG_PEM_DI
      RP_SR_CFG_INIT_MENU_SEL_PRG_PEM_JE: nonqueued-receiver-com-spec{data-element=CFG_INIT_MENU_SEL_PRG_PEM_JE, enable-update=0, handle-data-status=1, handle-never-received=0, init-value=CONST_tLOG_1:1}, required-interface=SR_CFG_INIT_MENU_SEL_PRG_PEM_JE
      RP_SR_CFG_INIT_MENU_SEL_PRG_PEM_LU: nonqueued-receiver-com-spec{data-element=CFG_INIT_MENU_SEL_PRG_PEM_LU, enable-update=0, handle-data-status=1, handle-never-received=0, init-value=CONST_tLOG_1:1}, required-interface=SR_CFG_INIT_MENU_SEL_PRG_PEM_LU
      RP_SR_CFG_INIT_MENU_SEL_PRG_PEM_MA: nonqueued-receiver-com-spec{data-element=CFG_INIT_MENU_SEL_PRG_PEM_MA, enable-update=0, handle-data-status=1, handle-never-received=0, init-value=CONST_tLOG_1:1}, required-interface=SR_CFG_INIT_MENU_SEL_PRG_PEM_MA
      RP_SR_CFG_INIT_MENU_SEL_PRG_PEM_ME: nonqueued-receiver-com-spec{data-element=CFG_INIT_MENU_SEL_PRG_PEM_ME, enable-update=0, handle-data-status=1, handle-never-received=0, init-value=CONST_tLOG_1:1}, required-interface=SR_CFG_INIT_MENU_SEL_PRG_PEM_ME
      RP_SR_CFG_INIT_MENU_SEL_PRG_PEM_SA: nonqueued-receiver-com-spec{data-element=CFG_INIT_MENU_SEL_PRG_PEM_SA, enable-update=0, handle-data-status=1, handle-never-received=0, init-value=CONST_tLOG_1:1}, required-interface=SR_CFG_INIT_MENU_SEL_PRG_PEM_SA
      RP_SR_CFG_INIT_MENU_SEL_PRG_PEM_VE: nonqueued-receiver-com-spec{data-element=CFG_INIT_MENU_SEL_PRG_PEM_VE, enable-update=0, handle-data-status=1, handle-never-received=0, init-value=CONST_tLOG_1:1}, required-interface=SR_CFG_INIT_MENU_SEL_PRG_PEM_VE
      RP_SR_CFG_INIT_MOTOR_VOLET: nonqueued-receiver-com-spec{data-element=CFG_INIT_MOTOR_VOLET, enable-update=0, handle-data-status=1, handle-never-received=0, init-value=CONST_tLOG_0:0}, required-interface=SR_CFG_INIT_MOTOR_VOLET
      RP_SR_CFG_INIT_PRESENCE_ARC: nonqueued-receiver-com-spec{data-element=CFG_INIT_PRESENCE_ARC, enable-update=0, handle-data-status=1, handle-never-received=0, init-value=CONST_tLOG_1:1}, required-interface=SR_CFG_INIT_PRESENCE_ARC
      RP_SR_CFG_INIT_PRV_MODE: nonqueued-receiver-com-spec{data-element=CFG_INIT_PRV_MODE, enable-update=0, handle-data-status=1, handle-never-received=0, init-value=0}, required-interface=SR_CFG_INIT_PRV_MODE
      RP_SR_CFG_INIT_RESERVE_ZEV: nonqueued-receiver-com-spec{data-element=CFG_INIT_RESERVE_ZEV, enable-update=0, handle-data-status=1, handle-never-received=0, init-value=2}, required-interface=SR_CFG_INIT_RESERVE_ZEV
      RP_SR_CFG_INIT_RTAB: nonqueued-receiver-com-spec{data-element=CFG_INIT_RTAB, enable-update=0, handle-data-status=1, handle-never-received=0, init-value=CONST_tLOG_1:1}, required-interface=SR_CFG_INIT_RTAB
      RP_SR_CFG_INIT_RTAB_ENERGY_REC: nonqueued-receiver-com-spec{data-element=CFG_INIT_RTAB_ENERGY_REC, enable-update=0, handle-data-status=1, handle-never-received=0, init-value=CONST_tBYTE_0:0}, required-interface=SR_CFG_INIT_RTAB_ENERGY_REC
      RP_SR_CFG_INIT_RTAB_RECHARGE: nonqueued-receiver-com-spec{data-element=CFG_INIT_RTAB_RECHARGE, enable-update=0, handle-data-status=1, handle-never-received=0, init-value=CONST_tLOG_0:0}, required-interface=SR_CFG_INIT_RTAB_RECHARGE
      RP_SR_CFG_INIT_RTAB_RECHARGE_H_DEB: nonqueued-receiver-com-spec{data-element=CFG_INIT_RTAB_RECHARGE_H_DEB, enable-update=0, handle-data-status=1, handle-never-received=0, init-value=CONST_tDWORD_0:0}, required-interface=SR_CFG_INIT_RTAB_RECHARGE_H_DEB
      RP_SR_CFG_INIT_RTAB_TYPE_REC: nonqueued-receiver-com-spec{data-element=CFG_INIT_RTAB_TYPE_REC, enable-update=0, handle-data-status=1, handle-never-received=0, init-value=CONST_tLOG_0:0}, required-interface=SR_CFG_INIT_RTAB_TYPE_REC
      RP_SR_CFG_INIT_SAM: nonqueued-receiver-com-spec{data-element=CFG_INIT_SAM, enable-update=0, handle-data-status=1, handle-never-received=0, init-value=CONST_tLOG_1:1}, required-interface=SR_CFG_INIT_SAM
      RP_SR_CFG_INIT_SELECTIVITE_CAB_ZC: nonqueued-receiver-com-spec{data-element=CFG_INIT_SELECTIVITE_CAB_ZC, enable-update=0, handle-data-status=1, handle-never-received=0, init-value=CONST_tLOG_0:0}, required-interface=SR_CFG_INIT_SELECTIVITE_CAB_ZC
      RP_SR_CFG_INIT_SELECTIVITE_COND: nonqueued-receiver-com-spec{data-element=CFG_INIT_SELECTIVITE_COND, enable-update=0, handle-data-status=1, handle-never-received=0, init-value=CONST_tLOG_0:0}, required-interface=SR_CFG_INIT_SELECTIVITE_COND
      RP_SR_CFG_INIT_SELECTIVITE_OUV_AR: nonqueued-receiver-com-spec{data-element=CFG_INIT_SELECTIVITE_OUV_AR, enable-update=0, handle-data-status=1, handle-never-received=0, init-value=CONST_tLOG_0:0}, required-interface=SR_CFG_INIT_SELECTIVITE_OUV_AR
      RP_SR_CFG_INIT_SEL_RESERVE_ZEV: nonqueued-receiver-com-spec{data-element=CFG_INIT_SEL_RESERVE_ZEV, enable-update=0, handle-data-status=1, handle-never-received=0, init-value=CONST_tLOG_1:1}, required-interface=SR_CFG_INIT_SEL_RESERVE_ZEV
      RP_SR_CFG_INIT_SENS_ARC_NIV: nonqueued-receiver-com-spec{data-element=CFG_INIT_SENS_ARC_NIV, enable-update=0, handle-data-status=1, handle-never-received=0, init-value=2}, required-interface=SR_CFG_INIT_SENS_ARC_NIV
      RP_SR_CFG_INIT_TCFG: nonqueued-receiver-com-spec{data-element=CFG_INIT_TCFG, enable-update=0, handle-data-status=1, handle-never-received=0, init-value=4}, required-interface=SR_CFG_INIT_TCFG
      RP_SR_CFG_INIT_TEMPO_ACCOMP: nonqueued-receiver-com-spec{data-element=CFG_INIT_TEMPO_ACCOMP, enable-update=0, handle-data-status=1, handle-never-received=0, init-value=1}, required-interface=SR_CFG_INIT_TEMPO_ACCOMP
      RP_SR_CFG_INIT_TEMPO_DECONDA: nonqueued-receiver-com-spec{data-element=CFG_INIT_TEMPO_DECONDA, enable-update=0, handle-data-status=1, handle-never-received=0, init-value=1}, required-interface=SR_CFG_INIT_TEMPO_DECONDA
      RP_SR_CFG_INIT_UNITE_CONSO: nonqueued-receiver-com-spec{data-element=CFG_INIT_UNITE_CONSO, enable-update=0, handle-data-status=1, handle-never-received=0, init-value=CONST_tLOG_0:0}, required-interface=SR_CFG_INIT_UNITE_CONSO
      RP_SR_CFG_INIT_UNITE_DISTANCE: nonqueued-receiver-com-spec{data-element=CFG_INIT_UNITE_DISTANCE, enable-update=0, handle-data-status=1, handle-never-received=0, init-value=CONST_tLOG_0:0}, required-interface=SR_CFG_INIT_UNITE_DISTANCE
      RP_SR_CFG_INIT_UNITE_TEMP: nonqueued-receiver-com-spec{data-element=CFG_INIT_UNITE_TEMP, enable-update=0, handle-data-status=1, handle-never-received=0, init-value=CONST_tLOG_0:0}, required-interface=SR_CFG_INIT_UNITE_TEMP
      RP_SR_CFG_INIT_UNITE_VOLUME: nonqueued-receiver-com-spec{data-element=CFG_INIT_UNITE_VOLUME, enable-update=0, handle-data-status=1, handle-never-received=0, init-value=CONST_tLOG_0:0}, required-interface=SR_CFG_INIT_UNITE_VOLUME
      RP_SR_CFG_INIT_VAM_ECS_MODE: nonqueued-receiver-com-spec{data-element=CFG_INIT_VAM_ECS_MODE, enable-update=0, handle-data-status=1, handle-never-received=0, init-value=CONST_tLOG_1:1}, required-interface=SR_CFG_INIT_VAM_ECS_MODE
      RP_SR_CFG_INIT_VITESSE_1: nonqueued-receiver-com-spec{data-element=CFG_INIT_VITESSE_1, enable-update=0, handle-data-status=1, handle-never-received=0, init-value=CONST_tBYTE_50:50}, required-interface=SR_CFG_INIT_VITESSE_1
      RP_SR_CFG_INIT_VITESSE_2: nonqueued-receiver-com-spec{data-element=CFG_INIT_VITESSE_2, enable-update=0, handle-data-status=1, handle-never-received=0, init-value=CONST_tBYTE_70:70}, required-interface=SR_CFG_INIT_VITESSE_2
      RP_SR_CFG_INIT_VITESSE_3: nonqueued-receiver-com-spec{data-element=CFG_INIT_VITESSE_3, enable-update=0, handle-data-status=1, handle-never-received=0, init-value=CONST_tBYTE_90:90}, required-interface=SR_CFG_INIT_VITESSE_3
      RP_SR_CFG_INIT_VITESSE_4: nonqueued-receiver-com-spec{data-element=CFG_INIT_VITESSE_4, enable-update=0, handle-data-status=1, handle-never-received=0, init-value=CONST_tBYTE_110:110}, required-interface=SR_CFG_INIT_VITESSE_4
      RP_SR_CFG_INIT_VITESSE_5: nonqueued-receiver-com-spec{data-element=CFG_INIT_VITESSE_5, enable-update=0, handle-data-status=1, handle-never-received=0, init-value=CONST_tBYTE_130:130}, required-interface=SR_CFG_INIT_VITESSE_5
      RP_SR_CFG_INIT_VIT_LVV_1: nonqueued-receiver-com-spec{data-element=CFG_INIT_VIT_LVV_1, enable-update=0, handle-data-status=1, handle-never-received=0, init-value=CONST_tBYTE_50:50}, required-interface=SR_CFG_INIT_VIT_LVV_1
      RP_SR_CFG_INIT_VIT_LVV_1_Miles: nonqueued-receiver-com-spec{data-element=CFG_INIT_VIT_LVV_1_Miles, enable-update=0, handle-data-status=1, handle-never-received=0, init-value=CONST_tBYTE_32:32}, required-interface=SR_CFG_INIT_VIT_LVV_1_Miles
      RP_SR_CFG_INIT_VIT_LVV_2: nonqueued-receiver-com-spec{data-element=CFG_INIT_VIT_LVV_2, enable-update=0, handle-data-status=1, handle-never-received=0, init-value=CONST_tBYTE_70:70}, required-interface=SR_CFG_INIT_VIT_LVV_2
      RP_SR_CFG_INIT_VIT_LVV_2_Miles: nonqueued-receiver-com-spec{data-element=CFG_INIT_VIT_LVV_2_Miles, enable-update=0, handle-data-status=1, handle-never-received=0, init-value=CONST_tBYTE_48:48}, required-interface=SR_CFG_INIT_VIT_LVV_2_Miles
      RP_SR_CFG_INIT_VIT_LVV_3: nonqueued-receiver-com-spec{data-element=CFG_INIT_VIT_LVV_3, enable-update=0, handle-data-status=1, handle-never-received=0, init-value=CONST_tBYTE_80:80}, required-interface=SR_CFG_INIT_VIT_LVV_3
      RP_SR_CFG_INIT_VIT_LVV_3_Miles: nonqueued-receiver-com-spec{data-element=CFG_INIT_VIT_LVV_3_Miles, enable-update=0, handle-data-status=1, handle-never-received=0, init-value=CONST_tBYTE_64:64}, required-interface=SR_CFG_INIT_VIT_LVV_3_Miles
      RP_SR_CFG_INIT_VIT_LVV_4: nonqueued-receiver-com-spec{data-element=CFG_INIT_VIT_LVV_4, enable-update=0, handle-data-status=1, handle-never-received=0, init-value=CONST_tBYTE_90:90}, required-interface=SR_CFG_INIT_VIT_LVV_4
      RP_SR_CFG_INIT_VIT_LVV_4_Miles: nonqueued-receiver-com-spec{data-element=CFG_INIT_VIT_LVV_4_Miles, enable-update=0, handle-data-status=1, handle-never-received=0, init-value=CONST_tBYTE_80:80}, required-interface=SR_CFG_INIT_VIT_LVV_4_Miles
      RP_SR_CFG_INIT_VIT_LVV_5: nonqueued-receiver-com-spec{data-element=CFG_INIT_VIT_LVV_5, enable-update=0, handle-data-status=1, handle-never-received=0, init-value=CONST_tBYTE_110:110}, required-interface=SR_CFG_INIT_VIT_LVV_5
      RP_SR_CFG_INIT_VIT_LVV_5_Miles: nonqueued-receiver-com-spec{data-element=CFG_INIT_VIT_LVV_5_Miles, enable-update=0, handle-data-status=1, handle-never-received=0, init-value=CONST_tBYTE_96:96}, required-interface=SR_CFG_INIT_VIT_LVV_5_Miles
      RP_SR_CFG_INIT_VIT_LVV_6: nonqueued-receiver-com-spec{data-element=CFG_INIT_VIT_LVV_6, enable-update=0, handle-data-status=1, handle-never-received=0, init-value=CONST_tBYTE_130:130}, required-interface=SR_CFG_INIT_VIT_LVV_6
      RP_SR_CFG_INIT_VIT_LVV_6_Miles: nonqueued-receiver-com-spec{data-element=CFG_INIT_VIT_LVV_6_Miles, enable-update=0, handle-data-status=1, handle-never-received=0, init-value=CONST_tBYTE_112:112}, required-interface=SR_CFG_INIT_VIT_LVV_6_Miles
      RP_SR_CFG_INIT_VIT_RVV_1: nonqueued-receiver-com-spec{data-element=CFG_INIT_VIT_RVV_1, enable-update=0, handle-data-status=1, handle-never-received=0, init-value=CONST_tBYTE_50:50}, required-interface=SR_CFG_INIT_VIT_RVV_1
      RP_SR_CFG_INIT_VIT_RVV_1_Miles: nonqueued-receiver-com-spec{data-element=CFG_INIT_VIT_RVV_1_Miles, enable-update=0, handle-data-status=1, handle-never-received=0, init-value=CONST_tBYTE_48:48}, required-interface=SR_CFG_INIT_VIT_RVV_1_Miles
      RP_SR_CFG_INIT_VIT_RVV_2: nonqueued-receiver-com-spec{data-element=CFG_INIT_VIT_RVV_2, enable-update=0, handle-data-status=1, handle-never-received=0, init-value=CONST_tBYTE_70:70}, required-interface=SR_CFG_INIT_VIT_RVV_2
      RP_SR_CFG_INIT_VIT_RVV_2_Miles: nonqueued-receiver-com-spec{data-element=CFG_INIT_VIT_RVV_2_Miles, enable-update=0, handle-data-status=1, handle-never-received=0, init-value=CONST_tBYTE_64:64}, required-interface=SR_CFG_INIT_VIT_RVV_2_Miles
      RP_SR_CFG_INIT_VIT_RVV_3: nonqueued-receiver-com-spec{data-element=CFG_INIT_VIT_RVV_3, enable-update=0, handle-data-status=1, handle-never-received=0, init-value=CONST_tBYTE_80:80}, required-interface=SR_CFG_INIT_VIT_RVV_3
      RP_SR_CFG_INIT_VIT_RVV_3_Miles: nonqueued-receiver-com-spec{data-element=CFG_INIT_VIT_RVV_3_Miles, enable-update=0, handle-data-status=1, handle-never-received=0, init-value=CONST_tBYTE_80:80}, required-interface=SR_CFG_INIT_VIT_RVV_3_Miles
      RP_SR_CFG_INIT_VIT_RVV_4: nonqueued-receiver-com-spec{data-element=CFG_INIT_VIT_RVV_4, enable-update=0, handle-data-status=1, handle-never-received=0, init-value=CONST_tBYTE_90:90}, required-interface=SR_CFG_INIT_VIT_RVV_4
      RP_SR_CFG_INIT_VIT_RVV_4_Miles: nonqueued-receiver-com-spec{data-element=CFG_INIT_VIT_RVV_4_Miles, enable-update=0, handle-data-status=1, handle-never-received=0, init-value=CONST_tBYTE_96:96}, required-interface=SR_CFG_INIT_VIT_RVV_4_Miles
      RP_SR_CFG_INIT_VIT_RVV_5: nonqueued-receiver-com-spec{data-element=CFG_INIT_VIT_RVV_5, enable-update=0, handle-data-status=1, handle-never-received=0, init-value=CONST_tBYTE_110:110}, required-interface=SR_CFG_INIT_VIT_RVV_5
      RP_SR_CFG_INIT_VIT_RVV_5_Miles: nonqueued-receiver-com-spec{data-element=CFG_INIT_VIT_RVV_5_Miles, enable-update=0, handle-data-status=1, handle-never-received=0, init-value=CONST_tBYTE_112:112}, required-interface=SR_CFG_INIT_VIT_RVV_5_Miles
      RP_SR_CFG_INIT_VIT_RVV_6: nonqueued-receiver-com-spec{data-element=CFG_INIT_VIT_RVV_6, enable-update=0, handle-data-status=1, handle-never-received=0, init-value=CONST_tBYTE_130:130}, required-interface=SR_CFG_INIT_VIT_RVV_6
      RP_SR_CFG_INIT_VIT_RVV_6_Miles: nonqueued-receiver-com-spec{data-element=CFG_INIT_VIT_RVV_6_Miles, enable-update=0, handle-data-status=1, handle-never-received=0, init-value=CONST_tBYTE_129:129}, required-interface=SR_CFG_INIT_VIT_RVV_6_Miles
      RP_SR_CFG_INIT_VTOR_IRV: nonqueued-receiver-com-spec{data-element=CFG_INIT_VTOR_IRV, enable-update=0, handle-data-status=1, handle-never-received=0, init-value=CONST_tLOG_0:0}, required-interface=SR_CFG_INIT_VTOR_IRV
      RP_SR_CFG_MECATRONIC_HEADLAMP: nonqueued-receiver-com-spec{data-element=CFG_MECATRONIC_HEADLAMP, enable-update=0, handle-data-status=1, handle-never-received=0, init-value=CONST_tLOG_0:0}, required-interface=SR_CFG_MECATRONIC_HEADLAMP
      RP_SR_CFG_OPTION_MENU_FSE: nonqueued-receiver-com-spec{data-element=CFG_OPTION_MENU_FSE, enable-update=0, handle-data-status=1, handle-never-received=0, init-value=CONST_tLOG_1:1}, required-interface=SR_CFG_OPTION_MENU_FSE
      RP_SR_CFG_PRESENCE_AFS: nonqueued-receiver-com-spec{data-element=CFG_PRESENCE_AFS, enable-update=0, handle-data-status=1, handle-never-received=0, init-value=CONST_tLOG_0:0}, required-interface=SR_CFG_PRESENCE_AFS
      RP_SR_CFG_PRESENCE_ARC: nonqueued-receiver-com-spec{data-element=CFG_PRESENCE_ARC, enable-update=0, handle-data-status=1, handle-never-received=0, init-value=CONST_t_cARC_0_1:1}, required-interface=SR_CFG_PRESENCE_ARC
      RP_SR_CFG_PRESENCE_FARC: nonqueued-receiver-com-spec{data-element=CFG_PRESENCE_FARC, enable-update=0, handle-data-status=1, handle-never-received=0, init-value=CONST_t_cFARC_0_0:0}, required-interface=SR_CFG_PRESENCE_FARC
      RP_SR_CFG_PRESENCE_MENU_PERSO: nonqueued-receiver-com-spec{data-element=CFG_PRESENCE_MENU_PERSO, enable-update=0, handle-data-status=1, handle-never-received=0, init-value=CONST_tBYTE_0:0}, required-interface=SR_CFG_PRESENCE_MENU_PERSO
      RP_SR_CFG_PRESENCE_TO: nonqueued-receiver-com-spec{data-element=CFG_PRESENCE_TO, enable-update=0, handle-data-status=1, handle-never-received=0, init-value=CONST_t_CFG_PRESENCE_TO_0:0}, required-interface=SR_CFG_PRESENCE_TO
      RP_SR_CFG_PRESENCE_TOUCHE_CONFIG: nonqueued-receiver-com-spec{data-element=CFG_PRESENCE_TOUCHE_CONFIG, enable-update=0, handle-data-status=1, handle-never-received=0, init-value=CONST_tLOG_0:0}, required-interface=SR_CFG_PRESENCE_TOUCHE_CONFIG
      RP_SR_CFG_TYPE_AAS: nonqueued-receiver-com-spec{data-element=CFG_TYPE_AAS, enable-update=0, handle-data-status=1, handle-never-received=0, init-value=CONST_CFG_TYPE_AAS_tBYTE_cAAS_Absent:0}, required-interface=SR_CFG_TYPE_AAS
      RP_SR_CFG_TYPE_ACTIVATION_AFS: nonqueued-receiver-com-spec{data-element=CFG_TYPE_ACTIVATION_AFS, enable-update=0, handle-data-status=1, handle-never-received=0, init-value=CONST_tLOG_0:0}, required-interface=SR_CFG_TYPE_ACTIVATION_AFS
      RP_SR_CFG_TYPE_FSE: nonqueued-receiver-com-spec{data-element=CFG_TYPE_FSE, enable-update=0, handle-data-status=1, handle-never-received=0, init-value=CONST_t_cTypeFSE_0:0}, required-interface=SR_CFG_TYPE_FSE
      RP_SR_CFG_TYPE_FUNCTIONAL_ABSD: nonqueued-receiver-com-spec{data-element=CFG_TYPE_FUNCTIONAL_ABSD, enable-update=0, handle-data-status=1, handle-never-received=0, init-value=CONST_CFG_TYPE_FUNCTIONAL_ABSD_t_cTYPE_FUNCTIONAL_ABSD_cTYPE_FUNCTIONAL_ABSD_EURONCAP:0}, required-interface=SR_CFG_TYPE_FUNCTIONAL_ABSD
      RP_SR_CFG_TYPE_REGLAGE_SELECTIVITE: nonqueued-receiver-com-spec{data-element=CFG_TYPE_REGLAGE_SELECTIVITE, enable-update=0, handle-data-status=1, handle-never-received=0, init-value=CONST_t_cGAV_Selectivite_0:0}, required-interface=SR_CFG_TYPE_REGLAGE_SELECTIVITE
      RP_SR_CFG_TYPE_SELECTIVITE: nonqueued-receiver-com-spec{data-element=CFG_TYPE_SELECTIVITE, enable-update=0, handle-data-status=1, handle-never-received=0, init-value=CONST_t_cTypeSelect_0:0}, required-interface=SR_CFG_TYPE_SELECTIVITE
      RP_SR_CFG_TYPE_SELECTIVITE_OUV_AR: nonqueued-receiver-com-spec{data-element=CFG_TYPE_SELECTIVITE_OUV_AR, enable-update=0, handle-data-status=1, handle-never-received=0, init-value=CONST_t_cTypeSelectOuvAR_0:0}, required-interface=SR_CFG_TYPE_SELECTIVITE_OUV_AR
      RP_SR_DispoDmdMenuPrgPem: nonqueued-receiver-com-spec{data-element=DispoDmdMenuPrgPem, enable-update=0, handle-data-status=1, handle-never-received=0, init-value=CONST_tLOG_0:0}, required-interface=SR_DispoDmdMenuPrgPem
      RP_SR_DmdDispoDmdMenuReserveZEV: nonqueued-receiver-com-spec{data-element=DmdDispoDmdMenuReserveZEV, enable-update=0, handle-data-status=1, handle-never-received=0, init-value=CONST_tLOG_0:0}, required-interface=SR_DmdDispoDmdMenuReserveZEV
      RP_SR_DmdmCGEPVOffReserveZEV: nonqueued-receiver-com-spec{data-element=DmdmCGEPVOffReserveZEV, enable-update=0, handle-data-status=1, handle-never-received=0, init-value=CONST_tLOG_0:0}, required-interface=SR_DmdmCGEPVOffReserveZEV
      RP_SR_DmdMenuAccueilCond: nonqueued-receiver-com-spec{data-element=DmdMenuAccueilCond, enable-update=0, handle-data-status=1, handle-never-received=0, init-value=CONST_tLOG_0:0}, required-interface=SR_DmdMenuAccueilCond
      RP_SR_DmdMenuActButee{1..5}XVV: nonqueued-receiver-com-spec{data-element=DmdMenuActButee{1..5}XVV, enable-update=0, handle-data-status=1, handle-never-received=0, init-value=CONST_tLOG_0:0}, required-interface=SR_DmdMenuActButee{1..5}XVV
      RP_SR_DmdMenuActButeeGenXVV: nonqueued-receiver-com-spec{data-element=DmdMenuActButeeGenXVV, enable-update=0, handle-data-status=1, handle-never-received=0, init-value=CONST_tLOG_0:0}, required-interface=SR_DmdMenuActButeeGenXVV
      RP_SR_DmdMenuARCSensNiv: nonqueued-receiver-com-spec{data-element=DmdMenuARCSensNiv, enable-update=0, handle-data-status=1, handle-never-received=0, init-value=CONST_tBILOG_2:2}, required-interface=SR_DmdMenuARCSensNiv
      RP_SR_DmdMenuBAAActivation: nonqueued-receiver-com-spec{data-element=DmdMenuBAAActivation, enable-update=0, handle-data-status=1, handle-never-received=0, init-value=CONST_tLOG_0:0}, required-interface=SR_DmdMenuBAAActivation
      RP_SR_DmdMenuBAAAutolocking: nonqueued-receiver-com-spec{data-element=DmdMenuBAAAutolocking, enable-update=0, handle-data-status=1, handle-never-received=0, init-value=CONST_tLOG_0:0}, required-interface=SR_DmdMenuBAAAutolocking
      RP_SR_DmdMenuClim_PrecondASAP: nonqueued-receiver-com-spec{data-element=DmdMenuClim_PrecondASAP, enable-update=0, handle-data-status=1, handle-never-received=0, init-value=CONST_tLOG_0:0}, required-interface=SR_DmdMenuClim_PrecondASAP
      RP_SR_DmdMenuCLIM_PrecondDi{1..4}: nonqueued-receiver-com-spec{data-element=DmdMenuCLIM_PrecondDi{1..4}, enable-update=0, handle-data-status=1, handle-never-received=0, init-value=CONST_tLOG_0:0}, required-interface=SR_DmdMenuCLIM_PrecondDi{1..4}
      RP_SR_DmdMenuCLIM_PrecondH{1..4}: nonqueued-receiver-com-spec{data-element=DmdMenuCLIM_PrecondH{1..4}, enable-update=0, handle-data-status=1, handle-never-received=0, init-value=CONST_tWORD_0:0}, required-interface=SR_DmdMenuCLIM_PrecondH{1..4}
      RP_SR_DmdMenuCLIM_PrecondJe{1..4}: nonqueued-receiver-com-spec{data-element=DmdMenuCLIM_PrecondJe{1..4}, enable-update=0, handle-data-status=1, handle-never-received=0, init-value=CONST_tLOG_0:0}, required-interface=SR_DmdMenuCLIM_PrecondJe{1..4}
      RP_SR_DmdMenuCLIM_PrecondLu{1..4}: nonqueued-receiver-com-spec{data-element=DmdMenuCLIM_PrecondLu{1..4}, enable-update=0, handle-data-status=1, handle-never-received=0, init-value=CONST_tLOG_0:0}, required-interface=SR_DmdMenuCLIM_PrecondLu{1..4}
      RP_SR_DmdMenuCLIM_PrecondMa{1..4}: nonqueued-receiver-com-spec{data-element=DmdMenuCLIM_PrecondMa{1..4}, enable-update=0, handle-data-status=1, handle-never-received=0, init-value=CONST_tLOG_0:0}, required-interface=SR_DmdMenuCLIM_PrecondMa{1..4}
      RP_SR_DmdMenuCLIM_PrecondMe{1..4}: nonqueued-receiver-com-spec{data-element=DmdMenuCLIM_PrecondMe{1..4}, enable-update=0, handle-data-status=1, handle-never-received=0, init-value=CONST_tLOG_0:0}, required-interface=SR_DmdMenuCLIM_PrecondMe{1..4}
      RP_SR_DmdMenuCLIM_PrecondOn{1..4}: nonqueued-receiver-com-spec{data-element=DmdMenuCLIM_PrecondOn{1..4}, enable-update=0, handle-data-status=1, handle-never-received=0, init-value=CONST_tLOG_0:0}, required-interface=SR_DmdMenuCLIM_PrecondOn{1..4}
      RP_SR_DmdMenuCLIM_PrecondSa{1..4}: nonqueued-receiver-com-spec{data-element=DmdMenuCLIM_PrecondSa{1..4}, enable-update=0, handle-data-status=1, handle-never-received=0, init-value=CONST_tLOG_0:0}, required-interface=SR_DmdMenuCLIM_PrecondSa{1..4}
      RP_SR_DmdMenuCLIM_PrecondVe{1..4}: nonqueued-receiver-com-spec{data-element=DmdMenuCLIM_PrecondVe{1..4}, enable-update=0, handle-data-status=1, handle-never-received=0, init-value=CONST_tLOG_0:0}, required-interface=SR_DmdMenuCLIM_PrecondVe{1..4}
      RP_SR_DmdMenuCMDM_DAE: nonqueued-receiver-com-spec{data-element=DmdMenuCMDM_DAE, enable-update=0, handle-data-status=1, handle-never-received=0, init-value=CONST_tLOG_0:0}, required-interface=SR_DmdMenuCMDM_DAE
      RP_SR_DmdMenuCMDM_DAE_4WD: nonqueued-receiver-com-spec{data-element=DmdMenuCMDM_DAE_4WD, enable-update=0, handle-data-status=1, handle-never-received=0, init-value=CONST_tLOG_0:0}, required-interface=SR_DmdMenuCMDM_DAE_4WD
      RP_SR_DmdMenuDAAActivation: nonqueued-receiver-com-spec{data-element=DmdMenuDAAActivation, enable-update=0, handle-data-status=1, handle-never-received=0, init-value=CONST_tLOG_0:0}, required-interface=SR_DmdMenuDAAActivation
      RP_SR_DmdMenuDSG: nonqueued-receiver-com-spec{data-element=DmdMenuDSG, enable-update=0, handle-data-status=1, handle-never-received=0, init-value=CONST_tLOG_0:0}, required-interface=SR_DmdMenuDSG
      RP_SR_DmdMenuEclAccomp: nonqueued-receiver-com-spec{data-element=DmdMenuEclAccomp, enable-update=0, handle-data-status=1, handle-never-received=0, init-value=CONST_tLOG_0:0}, required-interface=SR_DmdMenuEclAccomp
      RP_SR_DmdMenuEclAccompTempo: nonqueued-receiver-com-spec{data-element=DmdMenuEclAccompTempo, enable-update=0, handle-data-status=1, handle-never-received=0, init-value=CONST_tBILOG_0:0}, required-interface=SR_DmdMenuEclAccompTempo
      RP_SR_DmdMenuEclAdapt: nonqueued-receiver-com-spec{data-element=DmdMenuEclAdapt, enable-update=0, handle-data-status=1, handle-never-received=0, init-value=CONST_tLOG_0:0}, required-interface=SR_DmdMenuEclAdapt
      RP_SR_DmdMenuEclAmbi: nonqueued-receiver-com-spec{data-element=DmdMenuEclAmbi, enable-update=0, handle-data-status=1, handle-never-received=0, init-value=CONST_tLOG_0:0}, required-interface=SR_DmdMenuEclAmbi
      RP_SR_DmdMenuEclAmbiNiv: nonqueued-receiver-com-spec{data-element=DmdMenuEclAmbiNiv, enable-update=0, handle-data-status=1, handle-never-received=0, init-value=CONST_tBYTE_3:3}, required-interface=SR_DmdMenuEclAmbiNiv
      RP_SR_DmdMenuEclAuto: nonqueued-receiver-com-spec{data-element=DmdMenuEclAuto, enable-update=0, handle-data-status=1, handle-never-received=0, init-value=CONST_tLOG_0:0}, required-interface=SR_DmdMenuEclAuto
      RP_SR_DmdMenuEclAutoroute: nonqueued-receiver-com-spec{data-element=DmdMenuEclAutoroute, enable-update=0, handle-data-status=1, handle-never-received=0, init-value=CONST_tLOG_0:0}, required-interface=SR_DmdMenuEclAutoroute
      RP_SR_DmdMenuEclCaland: nonqueued-receiver-com-spec{data-element=DmdMenuEclCaland, enable-update=0, handle-data-status=1, handle-never-received=0, init-value=CONST_tLOG_0:0}, required-interface=SR_DmdMenuEclCaland
      RP_SR_DmdMenuEclDeconda: nonqueued-receiver-com-spec{data-element=DmdMenuEclDeconda, enable-update=0, handle-data-status=1, handle-never-received=0, init-value=CONST_tLOG_0:0}, required-interface=SR_DmdMenuEclDeconda
      RP_SR_DmdMenuEclDecondaTempo: nonqueued-receiver-com-spec{data-element=DmdMenuEclDecondaTempo, enable-update=0, handle-data-status=1, handle-never-received=0, init-value=CONST_tBILOG_0:0}, required-interface=SR_DmdMenuEclDecondaTempo
      RP_SR_DmdMenuECLI_PPC_ANIM: nonqueued-receiver-com-spec{data-element=DmdMenuECLI_PPC_ANIM, enable-update=0, handle-data-status=1, handle-never-received=0, init-value=CONST_tBYTE_0:0}, required-interface=SR_DmdMenuECLI_PPC_ANIM
      RP_SR_DmdMenuECLI_PPC_BLOC1: nonqueued-receiver-com-spec{data-element=DmdMenuECLI_PPC_BLOC1, enable-update=0, handle-data-status=1, handle-never-received=0, init-value=CONST_tLOG_0:0}, required-interface=SR_DmdMenuECLI_PPC_BLOC1
      RP_SR_DmdMenuECLI_PPC_COL1: nonqueued-receiver-com-spec{data-element=DmdMenuECLI_PPC_COL1, enable-update=0, handle-data-status=1, handle-never-received=0, init-value=CONST_tBYTE_0:0}, required-interface=SR_DmdMenuECLI_PPC_COL1
      RP_SR_DmdMenuECLX_AFS: nonqueued-receiver-com-spec{data-element=DmdMenuECLX_AFS, enable-update=0, handle-data-status=1, handle-never-received=0, init-value=CONST_tLOG_0:0}, required-interface=SR_DmdMenuECLX_AFS
      RP_SR_DmdMenuECLX_ARS: nonqueued-receiver-com-spec{data-element=DmdMenuECLX_ARS, enable-update=0, handle-data-status=1, handle-never-received=0, init-value=CONST_tLOG_0:0}, required-interface=SR_DmdMenuECLX_ARS
      RP_SR_DmdMenuECLX_ECL_CAFR: nonqueued-receiver-com-spec{data-element=DmdMenuECLX_ECL_CAFR, enable-update=0, handle-data-status=1, handle-never-received=0, init-value=CONST_tLOG_0:0}, required-interface=SR_DmdMenuECLX_ECL_CAFR
      RP_SR_DmdMenuEssuiVitMar: nonqueued-receiver-com-spec{data-element=DmdMenuEssuiVitMar, enable-update=0, handle-data-status=1, handle-never-received=0, init-value=CONST_tLOG_0:0}, required-interface=SR_DmdMenuEssuiVitMar
      RP_SR_DmdMenuFARC: nonqueued-receiver-com-spec{data-element=DmdMenuFARC, enable-update=0, handle-data-status=1, handle-never-received=0, init-value=CONST_tLOG_0:0}, required-interface=SR_DmdMenuFARC
      RP_SR_DmdMenuFeuxDiurne: nonqueued-receiver-com-spec{data-element=DmdMenuFeuxDiurne, enable-update=0, handle-data-status=1, handle-never-received=0, init-value=CONST_tLOG_0:0}, required-interface=SR_DmdMenuFeuxDiurne
      RP_SR_DmdMenuFSEAuto: nonqueued-receiver-com-spec{data-element=DmdMenuFSEAuto, enable-update=0, handle-data-status=1, handle-never-received=0, init-value=CONST_tLOG_0:0}, required-interface=SR_DmdMenuFSEAuto
      RP_SR_DmdMenuGAV_AMLA: nonqueued-receiver-com-spec{data-element=DmdMenuGAV_AMLA, enable-update=0, handle-data-status=1, handle-never-received=0, init-value=CONST_tLOG_0:0}, required-interface=SR_DmdMenuGAV_AMLA
      RP_SR_DmdMenuILV: nonqueued-receiver-com-spec{data-element=DmdMenuILV, enable-update=0, handle-data-status=1, handle-never-received=0, init-value=CONST_tLOG_0:0}, required-interface=SR_DmdMenuILV
      RP_SR_DmdMenuILV_ETSR: nonqueued-receiver-com-spec{data-element=DmdMenuILV_ETSR, enable-update=0, handle-data-status=1, handle-never-received=0, init-value=CONST_tLOG_0:0}, required-interface=SR_DmdMenuILV_ETSR
      RP_SR_DmdMenuIMA: nonqueued-receiver-com-spec{data-element=DmdMenuIMA, enable-update=0, handle-data-status=1, handle-never-received=0, init-value=CONST_tLOG_0:0}, required-interface=SR_DmdMenuIMA
      RP_SR_DmdMenuInfoLvvDispo: nonqueued-receiver-com-spec{data-element=DmdMenuInfoLvvDispo, enable-update=0, handle-data-status=1, handle-never-received=0, init-value=CONST_tLOG_0:0}, required-interface=SR_DmdMenuInfoLvvDispo
      RP_SR_DmdMenuInfoParamDispo: nonqueued-receiver-com-spec{data-element=DmdMenuInfoParamDispo, enable-update=0, handle-data-status=1, handle-never-received=0, init-value=CONST_tLOG_0:0}, required-interface=SR_DmdMenuInfoParamDispo
      RP_SR_DmdMenuInfoPrecondDispo: nonqueued-receiver-com-spec{data-element=DmdMenuInfoPrecondDispo, enable-update=0, handle-data-status=1, handle-never-received=0, init-value=CONST_tLOG_0:0}, required-interface=SR_DmdMenuInfoPrecondDispo
      RP_SR_DmdMenuInfoRechargeDispo: nonqueued-receiver-com-spec{data-element=DmdMenuInfoRechargeDispo, enable-update=0, handle-data-status=1, handle-never-received=0, init-value=CONST_tLOG_0:0}, required-interface=SR_DmdMenuInfoRechargeDispo
      RP_SR_DmdMenuInfoRvvDispo: nonqueued-receiver-com-spec{data-element=DmdMenuInfoRvvDispo, enable-update=0, handle-data-status=1, handle-never-received=0, init-value=CONST_tLOG_0:0}, required-interface=SR_DmdMenuInfoRvvDispo
      RP_SR_DmdMenuInfoUniteLangueDispo: nonqueued-receiver-com-spec{data-element=DmdMenuInfoUniteLangueDispo, enable-update=0, handle-data-status=1, handle-never-received=0, init-value=CONST_tLOG_0:0}, required-interface=SR_DmdMenuInfoUniteLangueDispo
      RP_SR_DmdMenuInfoXVVDispo: nonqueued-receiver-com-spec{data-element=DmdMenuInfoXVVDispo, enable-update=0, handle-data-status=1, handle-never-received=0, init-value=CONST_tLOG_0:0}, required-interface=SR_DmdMenuInfoXVVDispo
      RP_SR_DmdMenuINV_ADSD: nonqueued-receiver-com-spec{data-element=DmdMenuINV_ADSD, enable-update=0, handle-data-status=1, handle-never-received=0, init-value=CONST_tLOG_0:0}, required-interface=SR_DmdMenuINV_ADSD
      RP_SR_DmdMenuLangueVehicule: nonqueued-receiver-com-spec{data-element=DmdMenuLangueVehicule, enable-update=0, handle-data-status=1, handle-never-received=0, init-value=CONST_tBYTE_0:0}, required-interface=SR_DmdMenuLangueVehicule
      RP_SR_DmdMenuMotoVolAr: nonqueued-receiver-com-spec{data-element=DmdMenuMotoVolAr, enable-update=0, handle-data-status=1, handle-never-received=0, init-value=CONST_tLOG_0:0}, required-interface=SR_DmdMenuMotoVolAr
      RP_SR_DmdMenuPresenceARC: nonqueued-receiver-com-spec{data-element=DmdMenuPresenceARC, enable-update=0, handle-data-status=1, handle-never-received=0, init-value=CONST_tLOG_0:0}, required-interface=SR_DmdMenuPresenceARC
      RP_SR_DmdMenuPrgHcEnd: nonqueued-receiver-com-spec{data-element=DmdMenuPrgHcEnd, enable-update=0, handle-data-status=1, handle-never-received=0, init-value=CONST_tDWORD_0:0}, required-interface=SR_DmdMenuPrgHcEnd
      RP_SR_DmdMenuPrgHcStart: nonqueued-receiver-com-spec{data-element=DmdMenuPrgHcStart, enable-update=0, handle-data-status=1, handle-never-received=0, init-value=CONST_tDWORD_0:0}, required-interface=SR_DmdMenuPrgHcStart
      RP_SR_DmdMenuPrgPemDi: nonqueued-receiver-com-spec{data-element=DmdMenuPrgPemDi, enable-update=0, handle-data-status=1, handle-never-received=0, init-value=CONST_tDWORD_0:0}, required-interface=SR_DmdMenuPrgPemDi
      RP_SR_DmdMenuPrgPemJe: nonqueued-receiver-com-spec{data-element=DmdMenuPrgPemJe, enable-update=0, handle-data-status=1, handle-never-received=0, init-value=CONST_tDWORD_0:0}, required-interface=SR_DmdMenuPrgPemJe
      RP_SR_DmdMenuPrgPemLu: nonqueued-receiver-com-spec{data-element=DmdMenuPrgPemLu, enable-update=0, handle-data-status=1, handle-never-received=0, init-value=CONST_tDWORD_0:0}, required-interface=SR_DmdMenuPrgPemLu
      RP_SR_DmdMenuPrgPemMa: nonqueued-receiver-com-spec{data-element=DmdMenuPrgPemMa, enable-update=0, handle-data-status=1, handle-never-received=0, init-value=CONST_tDWORD_0:0}, required-interface=SR_DmdMenuPrgPemMa
      RP_SR_DmdMenuPrgPemMe: nonqueued-receiver-com-spec{data-element=DmdMenuPrgPemMe, enable-update=0, handle-data-status=1, handle-never-received=0, init-value=CONST_tDWORD_0:0}, required-interface=SR_DmdMenuPrgPemMe
      RP_SR_DmdMenuPrgPemSa: nonqueued-receiver-com-spec{data-element=DmdMenuPrgPemSa, enable-update=0, handle-data-status=1, handle-never-received=0, init-value=CONST_tDWORD_0:0}, required-interface=SR_DmdMenuPrgPemSa
      RP_SR_DmdMenuPrgPemVe: nonqueued-receiver-com-spec{data-element=DmdMenuPrgPemVe, enable-update=0, handle-data-status=1, handle-never-received=0, init-value=CONST_tDWORD_0:0}, required-interface=SR_DmdMenuPrgPemVe
      RP_SR_DmdMenuPRV_MODE: nonqueued-receiver-com-spec{data-element=DmdMenuPRV_MODE, enable-update=0, handle-data-status=1, handle-never-received=0, init-value=CONST_tBYTE_0:0}, required-interface=SR_DmdMenuPRV_MODE
      RP_SR_DmdMenuReserveZEV: nonqueued-receiver-com-spec{data-element=DmdMenuReserveZEV, enable-update=0, handle-data-status=1, handle-never-received=0, init-value=CONST_tBILOG_0:0}, required-interface=SR_DmdMenuReserveZEV
      RP_SR_DmdMenuRTAB_EnergyRec: nonqueued-receiver-com-spec{data-element=DmdMenuRTAB_EnergyRec, enable-update=0, handle-data-status=1, handle-never-received=0, init-value=CONST_tBYTE_0b01:0b01}, required-interface=SR_DmdMenuRTAB_EnergyRec
      RP_SR_DmdMenuRTAB_RechargeHDeb: nonqueued-receiver-com-spec{data-element=DmdMenuRTAB_RechargeHDeb, enable-update=0, handle-data-status=1, handle-never-received=0, init-value=CONST_tWORD_0:0}, required-interface=SR_DmdMenuRTAB_RechargeHDeb
      RP_SR_DmdMenuRTAB_TypeRec: nonqueued-receiver-com-spec{data-element=DmdMenuRTAB_TypeRec, enable-update=0, handle-data-status=1, handle-never-received=0, init-value=CONST_tLOG_0:0}, required-interface=SR_DmdMenuRTAB_TypeRec
      RP_SR_DmdMenuSelecArriere: nonqueued-receiver-com-spec{data-element=DmdMenuSelecArriere, enable-update=0, handle-data-status=1, handle-never-received=0, init-value=CONST_tLOG_0:0}, required-interface=SR_DmdMenuSelecArriere
      RP_SR_DmdMenuSelecCabine: nonqueued-receiver-com-spec{data-element=DmdMenuSelecCabine, enable-update=0, handle-data-status=1, handle-never-received=0, init-value=CONST_tLOG_0:0}, required-interface=SR_DmdMenuSelecCabine
      RP_SR_DmdMenuSelecOuvPlip: nonqueued-receiver-com-spec{data-element=DmdMenuSelecOuvPlip, enable-update=0, handle-data-status=1, handle-never-received=0, init-value=CONST_tLOG_0:0}, required-interface=SR_DmdMenuSelecOuvPlip
      RP_SR_DmdMenuSelPrgHc: nonqueued-receiver-com-spec{data-element=DmdMenuSelPrgHc, enable-update=0, handle-data-status=1, handle-never-received=0, init-value=CONST_tLOG_0:0}, required-interface=SR_DmdMenuSelPrgHc
      RP_SR_DmdMenuSelReserveZEV: nonqueued-receiver-com-spec{data-element=DmdMenuSelReserveZEV, enable-update=0, handle-data-status=1, handle-never-received=0, init-value=CONST_tLOG_0:0}, required-interface=SR_DmdMenuSelReserveZEV
      RP_SR_DmdMenuSonPoly: nonqueued-receiver-com-spec{data-element=DmdMenuSonPoly, enable-update=0, handle-data-status=1, handle-never-received=0, init-value=CONST_tBILOG_0:0}, required-interface=SR_DmdMenuSonPoly
      RP_SR_DmdMenuStatusAAS: nonqueued-receiver-com-spec{data-element=DmdMenuStatusAAS, enable-update=0, handle-data-status=1, handle-never-received=0, init-value=CONST_tLOG_0:0}, required-interface=SR_DmdMenuStatusAAS
      RP_SR_DmdMenuStatusSAM: nonqueued-receiver-com-spec{data-element=DmdMenuStatusSAM, enable-update=0, handle-data-status=1, handle-never-received=0, init-value=CONST_tLOG_0:0}, required-interface=SR_DmdMenuStatusSAM
      RP_SR_DmdMenuTCFG: nonqueued-receiver-com-spec{data-element=DmdMenuTCFG, enable-update=0, handle-data-status=1, handle-never-received=0, init-value=CONST_tBYTE_0:0}, required-interface=SR_DmdMenuTCFG
      RP_SR_DmdMenuUniteConso: nonqueued-receiver-com-spec{data-element=DmdMenuUniteConso, enable-update=0, handle-data-status=1, handle-never-received=0, init-value=CONST_tLOG_0:0}, required-interface=SR_DmdMenuUniteConso
      RP_SR_DmdMenuUniteDistance: nonqueued-receiver-com-spec{data-element=DmdMenuUniteDistance, enable-update=0, handle-data-status=1, handle-never-received=0, init-value=CONST_tLOG_0:0}, required-interface=SR_DmdMenuUniteDistance
      RP_SR_DmdMenuUniteTemperature: nonqueued-receiver-com-spec{data-element=DmdMenuUniteTemperature, enable-update=0, handle-data-status=1, handle-never-received=0, init-value=CONST_tLOG_0:0}, required-interface=SR_DmdMenuUniteTemperature
      RP_SR_DmdMenuUniteVolume: nonqueued-receiver-com-spec{data-element=DmdMenuUniteVolume, enable-update=0, handle-data-status=1, handle-never-received=0, init-value=CONST_tLOG_0:0}, required-interface=SR_DmdMenuUniteVolume
      RP_SR_DmdMenuVAM_ECS_MODE: nonqueued-receiver-com-spec{data-element=DmdMenuVAM_ECS_MODE, enable-update=0, handle-data-status=1, handle-never-received=0, init-value=CONST_tLOG_0:0}, required-interface=SR_DmdMenuVAM_ECS_MODE
      RP_SR_DmdMenuVitesse{1..5}XVV: nonqueued-receiver-com-spec{data-element=DmdMenuVitesse{1..5}XVV, enable-update=0, handle-data-status=1, handle-never-received=0, init-value=CONST_tBYTE_0:0}, required-interface=SR_DmdMenuVitesse{1..5}XVV
      RP_SR_DmdMenuVitLvv{1..6}: nonqueued-receiver-com-spec{data-element=DmdMenuVitLvv{1..6}, enable-update=0, handle-data-status=1, handle-never-received=0, init-value=CONST_tBYTE_0:0}, required-interface=SR_DmdMenuVitLvv{1..6}
      RP_SR_DmdMenuVitRvv{1..6}: nonqueued-receiver-com-spec{data-element=DmdMenuVitRvv{1..6}, enable-update=0, handle-data-status=1, handle-never-received=0, init-value=CONST_tBYTE_0:0}, required-interface=SR_DmdMenuVitRvv{1..6}
      RP_SR_DmdMenuVTOR_IRV: nonqueued-receiver-com-spec{data-element=DmdMenuVTOR_IRV, enable-update=0, handle-data-status=1, handle-never-received=0, init-value=CONST_tLOG_0:0}, required-interface=SR_DmdMenuVTOR_IRV
      RP_SR_EtatPrincipalSEV: nonqueued-receiver-com-spec{data-element=EtatPrincipalSEV, enable-update=0, handle-data-status=1, handle-never-received=0, init-value=CONST_EtatPrincipalSEV_t_SEV_SEV_Arret:105}, required-interface=SR_EtatPrincipalSEV
      RP_SR_MenuPersoMuet: nonqueued-receiver-com-spec{data-element=MenuPersoMuet, enable-update=0, handle-data-status=1, handle-never-received=0, init-value=CONST_tLOG_0:0}, required-interface=SR_MenuPersoMuet
      RP_SR_PhaseVieLS: nonqueued-receiver-com-spec{data-element=PhaseVieLS, enable-update=0, handle-data-status=1, handle-never-received=0, init-value=CONST_t_cCANLS_0:0}, required-interface=SR_PhaseVieLS
      RP_SR_RechargeTypeStatus: nonqueued-receiver-com-spec{data-element=RechargeTypeStatus, enable-update=0, handle-data-status=1, handle-never-received=0, init-value=CONST_RechargeTypeStatus_t_cRTABType_cRTABType_Standby:0}, required-interface=SR_RechargeTypeStatus
      RP_SR_T28_APPUI_LONG_TOUCHE_CONF: nonqueued-receiver-com-spec{data-element=T28_APPUI_LONG_TOUCHE_CONF, enable-update=0, handle-data-status=1, handle-never-received=0, init-value=CONST_tBYTE_2:2}, required-interface=SR_T28_APPUI_LONG_TOUCHE_CONF
      RP_SR_T28_MAINTIEN_DONNEES_TOUCHE: nonqueued-receiver-com-spec{data-element=T28_MAINTIEN_DONNEES_TOUCHE, enable-update=0, handle-data-status=1, handle-never-received=0, init-value=CONST_t_T28_MAINTIEN_DONNEES_TOUCHE_500:500}, required-interface=SR_T28_MAINTIEN_DONNEES_TOUCHE
      RP_SR_ToggleFrame21BRecue: nonqueued-receiver-com-spec{data-element=ToggleFrame21BRecue, enable-update=0, handle-data-status=1, handle-never-received=0, init-value=CONST_tLOG_0:0}, required-interface=SR_ToggleFrame21BRecue
      RP_SR_ToggleNewFrame15B: nonqueued-receiver-com-spec{data-element=ToggleNewFrame15B, enable-update=0, handle-data-status=1, handle-never-received=0, init-value=CONST_tLOG_0:0}, required-interface=SR_ToggleNewFrame15B
      RP_SR_ToggleNewFrame19B: nonqueued-receiver-com-spec{data-element=ToggleNewFrame19B, enable-update=0, handle-data-status=1, handle-never-received=0, init-value=CONST_tLOG_0:0}, required-interface=SR_ToggleNewFrame19B
      RP_SR_ToggleNewFrame1DB: nonqueued-receiver-com-spec{data-element=ToggleNewFrame1DB, enable-update=0, handle-data-status=1, handle-never-received=0, init-value=CONST_tLOG_0:0}, required-interface=SR_ToggleNewFrame1DB
      RP_SR_ToggleNewFrame25B29B: nonqueued-receiver-com-spec{data-element=ToggleNewFrame25B29B, enable-update=0, handle-data-status=1, handle-never-received=0, init-value=CONST_tLOG_0:0}, required-interface=SR_ToggleNewFrame25B29B
      RP_SR_ToggleNewFrame2DB: nonqueued-receiver-com-spec{data-element=ToggleNewFrame2DB, enable-update=0, handle-data-status=1, handle-never-received=0, init-value=CONST_tLOG_0:0}, required-interface=SR_ToggleNewFrame2DB
      RP_SR_VehicleLockingState: nonqueued-receiver-com-spec{data-element=VehicleLockingState, enable-update=0, handle-data-status=1, handle-never-received=0, init-value=CONST_tVehicleLockingState_0:0}, required-interface=SR_VehicleLockingState
      ASWC_A28_MSI: required-interface=AppModeInterface
